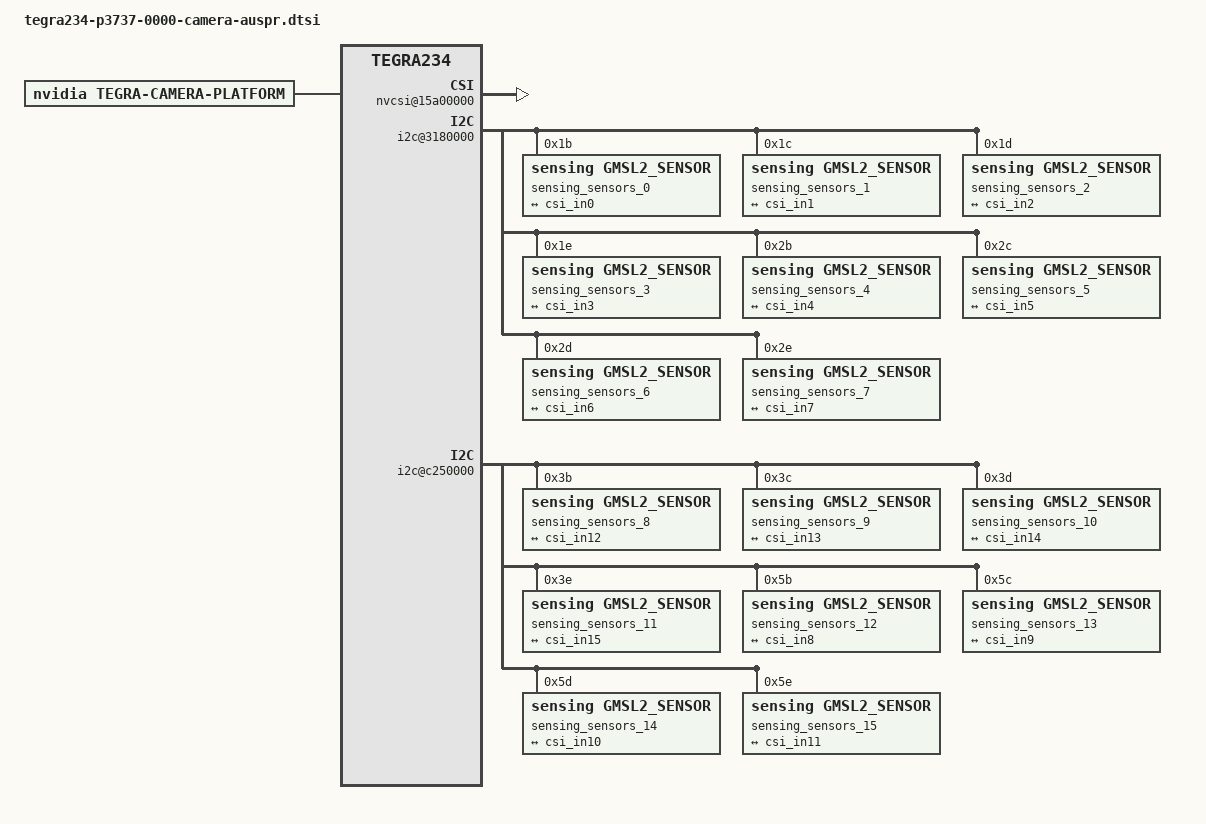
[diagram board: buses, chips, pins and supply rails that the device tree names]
/*
 * Top level DTS file for CVM:P3701-0000 and CVB:P3737-0000.
 *
 * Copyright (c) 2021-2023, NVIDIA CORPORATION.  All rights reserved.
 *
 * This program is free software; you can redistribute it and/or modify
 * it under the terms of the GNU General Public License as published by
 * the Free Software Foundation; version 2 of the License.
 *
 * This program is distributed in the hope that it will be useful, but WITHOUT
 * ANY WARRANTY; without even the implied warranty of MERCHANTABILITY or
 * FITNESS FOR A PARTICULAR PURPOSE.  See the GNU General Public License for
 * more details.
 */



/ {

	tegra-capture-vi {
		status = "okay";
        num-channels = <16>;
        ports {
          #address-cells = <1>;
          #size-cells = <0>;
          port@0 {
            reg = <0>;
            vi_in0: endpoint {
              port-index = <0>;
              bus-width = <4>;
              vc-id = <0>;
              remote-endpoint = <&csi_out0>;
            };
          };
          port@1 {
            reg = <1>;
            vi_in1: endpoint {
              port-index = <0>;
              bus-width = <4>;
              vc-id = <1>;
              remote-endpoint = <&csi_out1>;
            };
          };
          port@2 {
            reg = <2>;
            vi_in2: endpoint {
              port-index = <0>;
              bus-width = <4>;
              vc-id = <2>;
              remote-endpoint = <&csi_out2>;
            };
          };
          port@3 {
            reg = <3>;
            vi_in3: endpoint {
              port-index = <0>;
              bus-width = <4>;
              vc-id = <3>;
              remote-endpoint = <&csi_out3>;
            };
          };
          port@4 {
            reg = <4>;
            vi_in4: endpoint {
              port-index = <2>;
              bus-width = <4>;
              vc-id = <0>;
              remote-endpoint = <&csi_out4>;
            };
          };
          port@5 {
            reg = <5>;
            vi_in5: endpoint {
              port-index = <2>;
              bus-width = <4>;
              vc-id = <1>;
              remote-endpoint = <&csi_out5>;
            };
          };
          port@6 {
            reg = <6>;
            vi_in6: endpoint {
              port-index = <2>;
              bus-width = <4>;
              vc-id = <2>;
              remote-endpoint = <&csi_out6>;
            };
          };
          port@7 {
            reg = <7>;
            vi_in7: endpoint {
              port-index = <2>;
              bus-width = <4>;
              vc-id = <3>;
              remote-endpoint = <&csi_out7>;
            };
          };
          port@8 {
            reg = <8>;
            vi_in8: endpoint {
              port-index = <4>;
              bus-width = <4>;
              vc-id = <0>;
              remote-endpoint = <&csi_out8>;
            };
          };
          port@9 {
            reg = <9>;
            vi_in9: endpoint {
              port-index = <4>;
              bus-width = <4>;
              vc-id = <1>;
              remote-endpoint = <&csi_out9>;
            };
          };
          port@10 {
            reg = <10>;
            vi_in10: endpoint {
              port-index = <4>;
              bus-width = <4>;
              vc-id = <2>;
              remote-endpoint = <&csi_out10>;
            };
          };
          port@11 {
            reg = <11>;
            vi_in11: endpoint {
              port-index = <4>;
              bus-width = <4>;
              vc-id = <3>;
              remote-endpoint = <&csi_out11>;
            };
          };
          port@12 {
            reg = <12>;
            vi_in12: endpoint {
              port-index = <5>;
              bus-width = <4>;
              vc-id = <0>;
              remote-endpoint = <&csi_out12>;
            };
          };
		  port@13 {
            reg = <13>;
            vi_in13: endpoint {
              port-index = <5>;
              bus-width = <4>;
              vc-id = <1>;
              remote-endpoint = <&csi_out13>;
            };
          };
		  port@14 {
            reg = <14>;
            vi_in14: endpoint {
              port-index = <5>;
              bus-width = <4>;
              vc-id = <2>;
              remote-endpoint = <&csi_out14>;
            };
          };
		  port@15 {
            reg = <15>;
            vi_in15: endpoint {
              port-index = <5>;
              bus-width = <4>;
              vc-id = <3>;
              remote-endpoint = <&csi_out15>;
            };
          };
        };
	};


	//-------------------------------

	host1x@13e00000 {
		nvcsi@15a00000 {
			status = "okay";
        #address-cells = <1>;
        #size-cells = <0>;
        num-channels = <16>;
        channel@0 {
          reg = <0>;
          ports {
            #address-cells = <1>;
            #size-cells = <0>;
            port@0 {
              reg = <0>;
              csi_in0: endpoint@0 {
                port-index = <0>;
                bus-width = <4>;
                remote-endpoint = <&camera_out0>;
              };
            };
            port@1 {
              reg = <1>;
              csi_out0: endpoint@1 {
                remote-endpoint = <&vi_in0>;
              };
            };
          };
        };
        channel@1 {
          reg = <1>;
          ports {
            #address-cells = <1>;
            #size-cells = <0>;
            port@0 {
              reg = <0>;
              csi_in1: endpoint@0 {
                port-index = <0>;
                bus-width = <4>;
                remote-endpoint = <&camera_out1>;
              };
            };
            port@1 {
              reg = <1>;
              csi_out1: endpoint@1 {
                remote-endpoint = <&vi_in1>;
              };
            };
          };
        };
        channel@2 {
          reg = <2>;
          ports {
            #address-cells = <1>;
            #size-cells = <0>;
            port@0 {
              reg = <0>;
              csi_in2: endpoint@0 {
                port-index = <0>;
                bus-width = <4>;
                remote-endpoint = <&camera_out2>;
              };
            };
            port@1 {
              reg = <1>;
              csi_out2: endpoint@1 {
                remote-endpoint = <&vi_in2>;
              };
            };
          };
        };
        channel@3 {
          reg = <3>;
          ports {
            #address-cells = <1>;
            #size-cells = <0>;
            port@0 {
              reg = <0>;
              csi_in3: endpoint@0 {
                port-index = <0>;
                bus-width = <4>;
                remote-endpoint = <&camera_out3>;
              };
            };
            port@1 {
              reg = <1>;
              csi_out3: endpoint@1 {
                remote-endpoint = <&vi_in3>;
              };
            };
          };
        };      
        channel@4 {
          reg = <4>;
          ports {
            #address-cells = <1>;
            #size-cells = <0>;
            port@0 {
              reg = <0>;
              csi_in4: endpoint@0 {
                port-index = <2>;
                bus-width = <4>;
                remote-endpoint = <&camera_out4>;
              };
            };
            port@1 {
              reg = <1>;
              csi_out4: endpoint@1 {
                remote-endpoint = <&vi_in4>;
              };
            };
          };
        };
        channel@5 {
          reg = <5>;
          ports {
            #address-cells = <1>;
            #size-cells = <0>;
            port@0 {
              reg = <0>;              
              csi_in5: endpoint@0 {
                port-index = <2>;
                bus-width = <4>;
                remote-endpoint = <&camera_out5>;
              };
            };
            port@1 {
              reg = <1>;
              csi_out5: endpoint@1 {
                remote-endpoint = <&vi_in5>;
              };
            };
          };
        };
        channel@6 {
          reg = <6>;
          ports {
            #address-cells = <1>;
            #size-cells = <0>;
            port@0 {
              reg = <0>;
              csi_in6: endpoint@0 {
                port-index = <2>;
                bus-width = <4>;
                remote-endpoint = <&camera_out6>;
              };
            };
            port@1 {
              reg = <1>;
              csi_out6: endpoint@1 {
                remote-endpoint = <&vi_in6>;
              };
            };
          };
        };
        channel@7 {
          reg = <7>;
          ports {
            #address-cells = <1>;
            #size-cells = <0>;
            port@0 {
              reg = <0>;
              csi_in7: endpoint@0 {
                port-index = <2>;
                bus-width = <4>;
                remote-endpoint = <&camera_out7>;
              };
            };
            port@1 {
              reg = <1>;
              csi_out7: endpoint@1 {
                remote-endpoint = <&vi_in7>;
              };
            };
          };
        }; 
        channel@8 {
          reg = <8>;
          ports {
            #address-cells = <1>;
            #size-cells = <0>;
            port@0 {
              reg = <0>;
              csi_in8: endpoint@0 {
                port-index = <4>;
                vc-id = <0>;
                bus-width = <4>;
                remote-endpoint = <&camera_out12>; // workaround for SerDes 2&3 MIPI layout reversed
              };
            };
            port@1 {
              reg = <1>;
              csi_out8: endpoint@1 {
                remote-endpoint = <&vi_in8>;
              };
            };
          };
        };
        channel@9 {
          reg = <9>;
          ports {
            #address-cells = <1>;
            #size-cells = <0>;
            port@0 {
              reg = <0>;
              csi_in9: endpoint@0 {
                port-index = <4>;
                vc-id = <1>;
                bus-width = <4>;
                remote-endpoint = <&camera_out13>; // workaround for SerDes 2&3 MIPI layout reversed
              };
            };
            port@1 {
              reg = <1>;
              csi_out9: endpoint@1 {
                remote-endpoint = <&vi_in9>;
              };
            };
          };
        };
        channel@10 {
          reg = <10>;
          ports {
            #address-cells = <1>;
            #size-cells = <0>;
            port@0 {
              reg = <0>;
              csi_in10: endpoint@0 {
                port-index = <4>;
                vc-id = <2>;
                bus-width = <4>;
                remote-endpoint = <&camera_out14>; // workaround for SerDes 2&3 MIPI layout reversed
              };
            };
            port@1 {
              reg = <1>;
              csi_out10: endpoint@1 {
                remote-endpoint = <&vi_in10>;
              };
            };
          };
        };
        channel@11 {
          reg = <11>;
          ports {
            #address-cells = <1>;
            #size-cells = <0>;
            port@0 {
              reg = <0>;
              csi_in11: endpoint@0 {
                port-index = <4>;
                vc-id = <3>;
                bus-width = <4>;
                remote-endpoint = <&camera_out15>; // workaround for SerDes 2&3 MIPI layout reversed
              };
            };
            port@1 {
              reg = <1>;
              csi_out11: endpoint@1 {
                remote-endpoint = <&vi_in11>;
              };
            };
          };
        };
        channel@12 {
          reg = <12>;
          ports {
            #address-cells = <1>;
            #size-cells = <0>;
            port@0 {
              reg = <0>;
              csi_in12: endpoint@0 {
                port-index = <6>;
                vc-id = <0>;
                bus-width = <4>;
                remote-endpoint = <&camera_out8>; // workaround for SerDes 2&3 MIPI layout reversed
              };
            };
            port@1 {
              reg = <1>;
              csi_out12: endpoint@1 {
                remote-endpoint = <&vi_in12>;
              };
            };
          };
        };
        channel@13 {
          reg = <13>;
          ports {
            #address-cells = <1>;
            #size-cells = <0>;
            port@0 {
              reg = <0>;
              csi_in13: endpoint@0 {
                port-index = <6>;
                vc-id = <1>;
                bus-width = <4>;
                remote-endpoint = <&camera_out9>; // workaround for SerDes 2&3 MIPI layout reversed
              };
            };
            port@1 {
              reg = <1>;
              csi_out13: endpoint@1 {
                remote-endpoint = <&vi_in13>;
              };
            };
          };
        };
        channel@14 {
          reg = <14>;
          ports {
            #address-cells = <1>;
            #size-cells = <0>;
            port@0 {
              reg = <0>;
              csi_in14: endpoint@0 {
                port-index = <6>;
                vc-id = <2>;
                bus-width = <4>;
                remote-endpoint = <&camera_out10>; // workaround for SerDes 2&3 MIPI layout reversed
              };
            };
            port@1 {
              reg = <1>;
              csi_out14: endpoint@1 {
                remote-endpoint = <&vi_in14>;
              };
            };
          };
        };
        channel@15 {
          reg = <15>;
          ports {
            #address-cells = <1>;
            #size-cells = <0>;
            port@0 {
              reg = <0>;
              csi_in15: endpoint@0 {
                port-index = <6>;
                vc-id = <3>;
                bus-width = <4>;
                remote-endpoint = <&camera_out11>; // workaround for SerDes 2&3 MIPI layout reversed
              };
            };
            port@1 {
              reg = <1>;
              csi_out15: endpoint@1 {
                remote-endpoint = <&vi_in15>;
              };
            };
          };
        };
		};
	};

	//--------------------
	i2c@3180000 {
		sensing_sensors_0 {
					status = "okay";
  					compatible = "sensing,gmsl2_sensor";
					clocks = <&bpmp_clks TEGRA234_CLK_EXTPERIPH1>,
							 <&bpmp_clks TEGRA234_CLK_EXTPERIPH1>;
					clock-names = "extperiph1", "pllp_grtba";
					mclk = "extperiph1";
					
  					reg = <0x1b>;
					
  					devnode = "video0";
  
  					/* Physical dimensions of sensor */
  					physical_w = "15.0";
  					physical_h = "12.5";
  					sensor_model = "gmsl2_sensor";
  
  					/* Defines number of frames to be dropped by driver internally after applying */
  					/* sensor crop settings. Some sensors send corrupt frames after applying */
  					/* crop co-ordinates */
  					post_crop_frame_drop = "0";
  
  					/* Convert Gain to unit of dB (decibel) befor passing to kernel driver */
  					use_decibel_gain = "true";
  
  					/* enable CID_SENSOR_MODE_ID for sensor modes selection */
  					use_sensor_mode_id = "false";
  
  					mode0 {
  						mclk_khz = "24000";
  						num_lanes = "4";
  						tegra_sinterface = "serial_a";
  						vc_id = "0";
  						discontinuous_clk = "no";
  						dpcm_enable = "false";
  						cil_settletime = "0";
  						dynamic_pixel_bit_depth = "16";
  						csi_pixel_bit_depth = "16";
  						mode_type = "yuv";
  						pixel_phase = "uyvy";
  
  						active_w = "2880";
  						active_h = "1860";
  						readout_orientation = "0";
  						line_length = "2880";
  						inherent_gain = "1";
  						mclk_multiplier = "6.696";
  						pix_clk_hz = "160704000";
  						serdes_pix_clk_hz = "375000000";
  
  						gain_factor = "10";
  						min_gain_val = "0"; /* dB */
  						max_gain_val = "300"; /* dB */
  						step_gain_val = "3"; /* 0.3 */
  						default_gain = "0";
  						min_hdr_ratio = "1";
  						max_hdr_ratio = "1";
  						framerate_factor = "1000000";
  						min_framerate = "30000000";
  						max_framerate = "30000000";
  						step_framerate = "1";
  						default_framerate = "30000000";
  						exposure_factor = "1000000";
  						min_exp_time = "59"; /*us, 2 lines*/
  						max_exp_time = "33333";
  						step_exp_time = "1";
  						default_exp_time = "33333";/* us */
  						embedded_metadata_height = "0";
  					};
  
  					mode1 {
  						mclk_khz = "24000";
  						num_lanes = "4";
  						tegra_sinterface = "serial_a";
  						vc_id = "0";
  						discontinuous_clk = "yes";
  						dpcm_enable = "false";
  						cil_settletime = "0";
  						dynamic_pixel_bit_depth = "16";
  						csi_pixel_bit_depth = "16";
  						mode_type = "yuv";
  						pixel_phase = "uyvy";
  
  						active_w = "3840";
  						active_h = "2160";
  						readout_orientation = "0";
  						line_length = "3840";
  						inherent_gain = "1";
  						mclk_multiplier = "10.368";
  						pix_clk_hz = "248832000";
  						serdes_pix_clk_hz = "600000000";
  
  						gain_factor = "10";
  						min_gain_val = "0"; /* dB */
  						max_gain_val = "300"; /* dB */
  						step_gain_val = "3"; /* 0.3 */
  						default_gain = "0";
  						min_hdr_ratio = "1";
  						max_hdr_ratio = "1";
  						framerate_factor = "1000000";
  						min_framerate = "30000000";
  						max_framerate = "30000000";
  						step_framerate = "1";
  						default_framerate = "30000000";
  						exposure_factor = "1000000";
  						min_exp_time = "59"; /*us, 2 lines*/
  						max_exp_time = "33333";
  						step_exp_time = "1";
  						default_exp_time = "33333";/* us */
  						embedded_metadata_height = "0";
  					};
  
  					mode2 {
  						mclk_khz = "24000";
  						num_lanes = "4";
  						tegra_sinterface = "serial_a";
  						vc_id = "0";
  						discontinuous_clk = "no";
  						dpcm_enable = "false";
  						cil_settletime = "0";
  						dynamic_pixel_bit_depth = "16";
  						csi_pixel_bit_depth = "16";
  						mode_type = "yuv";
  						pixel_phase = "uyvy";
  
  						active_w = "1920";
  						active_h = "1536";
  						readout_orientation = "0";
  						line_length = "1920";
  						inherent_gain = "1";
  						mclk_multiplier = "3.6864";
  						pix_clk_hz = "88473600";
  						serdes_pix_clk_hz = "375000000";
  
  						gain_factor = "10";
  						min_gain_val = "0"; /* dB */
  						max_gain_val = "300"; /* dB */
  						step_gain_val = "3"; /* 0.3 */
  						default_gain = "0";
  						min_hdr_ratio = "1";
  						max_hdr_ratio = "1";
  						framerate_factor = "1000000";
  						min_framerate = "30000000";
  						max_framerate = "30000000";
  						step_framerate = "1";
  						default_framerate = "30000000";
  						exposure_factor = "1000000";
  						min_exp_time = "59"; /*us, 2 lines*/
  						max_exp_time = "33333";
  						step_exp_time = "1";
  						default_exp_time = "33333";/* us */
  						embedded_metadata_height = "0";
  					};
  
  					mode3 {
  						mclk_khz = "24000";
  						num_lanes = "4";
  						tegra_sinterface = "serial_a";
  						vc_id = "0";
  						discontinuous_clk = "no";
  						dpcm_enable = "false";
  						cil_settletime = "0";
  						dynamic_pixel_bit_depth = "16";
  						csi_pixel_bit_depth = "16";
  						mode_type = "yuv";
  						pixel_phase = "uyvy";
  
  						active_w = "1600";
  						active_h = "1300";
  						readout_orientation = "0";
  						line_length = "1600";
  						inherent_gain = "1";
  						mclk_multiplier = "2.6";
  						pix_clk_hz = "62400000";
  						serdes_pix_clk_hz = "375000000";
  
  						gain_factor = "10";
  						min_gain_val = "0"; /* dB */
  						max_gain_val = "300"; /* dB */
  						step_gain_val = "3"; /* 0.3 */
  						default_gain = "0";
  						min_hdr_ratio = "1";
  						max_hdr_ratio = "1";
  						framerate_factor = "1000000";
  						min_framerate = "30000000";
  						max_framerate = "30000000";
  						step_framerate = "1";
  						default_framerate = "30000000";
  						exposure_factor = "1000000";
  						min_exp_time = "59"; /*us, 2 lines*/
  						max_exp_time = "33333";
  						step_exp_time = "1";
  						default_exp_time = "33333";/* us */
  						embedded_metadata_height = "0";
  					};
  
  					ports {
  						#address-cells = <1>;
  						#size-cells = <0>;
  						port@0 {
  							reg = <0>;
  							camera_out0: endpoint {
  								vc-id = <0>;
  								port-index = <0>;
  								bus-width = <4>;
  								remote-endpoint = <&csi_in0>;
  							};
  						};
  					};
				  };
				  
  				sensing_sensors_1 {
					status = "okay";
  					compatible = "sensing,gmsl2_sensor";
					clocks = <&bpmp_clks TEGRA234_CLK_EXTPERIPH1>,
							 <&bpmp_clks TEGRA234_CLK_EXTPERIPH1>;
					clock-names = "extperiph1", "pllp_grtba";
					mclk = "extperiph1";
  					reg = <0x1c>;
  
  					devnode = "video1";
  
  					/* Physical dimensions of sensor */
  					physical_w = "15.0";
  					physical_h = "12.5";
  					sensor_model = "gmsl2_sensor";
  
  					/* Defines number of frames to be dropped by driver internally after applying */
  					/* sensor crop settings. Some sensors send corrupt frames after applying */
  					/* crop co-ordinates */
  					post_crop_frame_drop = "0";
  
  					/* Convert Gain to unit of dB (decibel) befor passing to kernel driver */
  					use_decibel_gain = "true";
  
  					/* enable CID_SENSOR_MODE_ID for sensor modes selection */
  					use_sensor_mode_id = "false";
  
  					mode0 {
  						mclk_khz = "24000";
  						num_lanes = "4";
  						tegra_sinterface = "serial_a";
  						vc_id = "1";
  						discontinuous_clk = "no";
  						dpcm_enable = "false";
  						cil_settletime = "0";
  						dynamic_pixel_bit_depth = "16";
  						csi_pixel_bit_depth = "16";
  						mode_type = "yuv";
  						pixel_phase = "uyvy";
  
  						active_w = "2880";
  						active_h = "1860";
  						readout_orientation = "0";
  						line_length = "2880";
  						inherent_gain = "1";
  						mclk_multiplier = "6.696";
  						pix_clk_hz = "160704000";
  						serdes_pix_clk_hz = "375000000";
  
  						gain_factor = "10";
  						min_gain_val = "0"; /* dB */
  						max_gain_val = "300"; /* dB */
  						step_gain_val = "3"; /* 0.3 */
  						default_gain = "0";
  						min_hdr_ratio = "1";
  						max_hdr_ratio = "1";
  						framerate_factor = "1000000";
  						min_framerate = "30000000";
  						max_framerate = "30000000";
  						step_framerate = "1";
  						default_framerate = "30000000";
  						exposure_factor = "1000000";
  						min_exp_time = "59"; /*us, 2 lines*/
  						max_exp_time = "33333";
  						step_exp_time = "1";
  						default_exp_time = "33333";/* us */
  						embedded_metadata_height = "0";
  					};
  
  					mode1 {
  						mclk_khz = "24000";
  						num_lanes = "4";
  						tegra_sinterface = "serial_a";
  						vc_id = "1";
  						discontinuous_clk = "yes";
  						dpcm_enable = "false";
  						cil_settletime = "0";
  						dynamic_pixel_bit_depth = "16";
  						csi_pixel_bit_depth = "16";
  						mode_type = "yuv";
  						pixel_phase = "uyvy";
  
  						active_w = "3840";
  						active_h = "2160";
  						readout_orientation = "0";
  						line_length = "3840";
  						inherent_gain = "1";
  						mclk_multiplier = "10.368";
  						pix_clk_hz = "248832000";
  						serdes_pix_clk_hz = "600000000";
  
  						gain_factor = "10";
  						min_gain_val = "0"; /* dB */
  						max_gain_val = "300"; /* dB */
  						step_gain_val = "3"; /* 0.3 */
  						default_gain = "0";
  						min_hdr_ratio = "1";
  						max_hdr_ratio = "1";
  						framerate_factor = "1000000";
  						min_framerate = "30000000";
  						max_framerate = "30000000";
  						step_framerate = "1";
  						default_framerate = "30000000";
  						exposure_factor = "1000000";
  						min_exp_time = "59"; /*us, 2 lines*/
  						max_exp_time = "33333";
  						step_exp_time = "1";
  						default_exp_time = "33333";/* us */
  						embedded_metadata_height = "0";
  					};
  
  					mode2 {
  						mclk_khz = "24000";
  						num_lanes = "4";
  						tegra_sinterface = "serial_a";
  						vc_id = "1";
  						discontinuous_clk = "no";
  						dpcm_enable = "false";
  						cil_settletime = "0";
  						dynamic_pixel_bit_depth = "16";
  						csi_pixel_bit_depth = "16";
  						mode_type = "yuv";
  						pixel_phase = "uyvy";
  
  						active_w = "1920";
  						active_h = "1536";
  						readout_orientation = "0";
  						line_length = "1920";
  						inherent_gain = "1";
  						mclk_multiplier = "3.6864";
  						pix_clk_hz = "88473600";
  						serdes_pix_clk_hz = "375000000";
  
  						gain_factor = "10";
  						min_gain_val = "0"; /* dB */
  						max_gain_val = "300"; /* dB */
  						step_gain_val = "3"; /* 0.3 */
  						default_gain = "0";
  						min_hdr_ratio = "1";
  						max_hdr_ratio = "1";
  						framerate_factor = "1000000";
  						min_framerate = "30000000";
  						max_framerate = "30000000";
  						step_framerate = "1";
  						default_framerate = "30000000";
  						exposure_factor = "1000000";
  						min_exp_time = "59"; /*us, 2 lines*/
  						max_exp_time = "33333";
  						step_exp_time = "1";
  						default_exp_time = "33333";/* us */
  						embedded_metadata_height = "0";
  					};
  
  					mode3 {
  						mclk_khz = "24000";
  						num_lanes = "4";
  						tegra_sinterface = "serial_a";
  						vc_id = "1";
  						discontinuous_clk = "no";
  						dpcm_enable = "false";
  						cil_settletime = "0";
  						dynamic_pixel_bit_depth = "16";
  						csi_pixel_bit_depth = "16";
  						mode_type = "yuv";
  						pixel_phase = "uyvy";
  
  						active_w = "1600";
  						active_h = "1300";
  						readout_orientation = "0";
  						line_length = "1600";
  						inherent_gain = "1";
  						mclk_multiplier = "2.6";
  						pix_clk_hz = "62400000";
  						serdes_pix_clk_hz = "375000000";
  
  						gain_factor = "10";
  						min_gain_val = "0"; /* dB */
  						max_gain_val = "300"; /* dB */
  						step_gain_val = "3"; /* 0.3 */
  						default_gain = "0";
  						min_hdr_ratio = "1";
  						max_hdr_ratio = "1";
  						framerate_factor = "1000000";
  						min_framerate = "30000000";
  						max_framerate = "30000000";
  						step_framerate = "1";
  						default_framerate = "30000000";
  						exposure_factor = "1000000";
  						min_exp_time = "59"; /*us, 2 lines*/
  						max_exp_time = "33333";
  						step_exp_time = "1";
  						default_exp_time = "33333";/* us */
  						embedded_metadata_height = "0";
  					};
  
  					ports {
  						#address-cells = <1>;
  						#size-cells = <0>;
  						port@0 {
  							reg = <0>;
  							camera_out1: endpoint {
  								vc-id = <1>;
  								port-index = <0>;
  								bus-width = <4>;
  								remote-endpoint = <&csi_in1>;
  							};
  						};
  					};
  				};
  
  				sensing_sensors_2 {
					status = "okay";
  					compatible = "sensing,gmsl2_sensor";
					clocks = <&bpmp_clks TEGRA234_CLK_EXTPERIPH1>,
							 <&bpmp_clks TEGRA234_CLK_EXTPERIPH1>;
					clock-names = "extperiph1", "pllp_grtba";
					mclk = "extperiph1";
  					reg = <0x1d>;
  
  					devnode = "video2";
  
  					/* Physical dimensions of sensor */
  					physical_w = "15.0";
  					physical_h = "12.5";
  					sensor_model = "gmsl2_sensor";
  
  					/* Defines number of frames to be dropped by driver internally after applying */
  					/* sensor crop settings. Some sensors send corrupt frames after applying */
  					/* crop co-ordinates */
  					post_crop_frame_drop = "0";
  
  					/* Convert Gain to unit of dB (decibel) befor passing to kernel driver */
  					use_decibel_gain = "true";
  
  					/* enable CID_SENSOR_MODE_ID for sensor modes selection */
  					use_sensor_mode_id = "false";
  
  					mode0 {
  						mclk_khz = "24000";
  						num_lanes = "4";
  						tegra_sinterface = "serial_a";
  						vc_id = "2";
  						discontinuous_clk = "no";
  						dpcm_enable = "false";
  						cil_settletime = "0";
  						dynamic_pixel_bit_depth = "16";
  						csi_pixel_bit_depth = "16";
  						mode_type = "yuv";
  						pixel_phase = "uyvy";
  
  						active_w = "2880";
  						active_h = "1860";
  						readout_orientation = "0";
  						line_length = "2880";
  						inherent_gain = "1";
  						mclk_multiplier = "6.696";
  						pix_clk_hz = "160704000";
  						serdes_pix_clk_hz = "375000000";
  
  						gain_factor = "10";
  						min_gain_val = "0"; /* dB */
  						max_gain_val = "300"; /* dB */
  						step_gain_val = "3"; /* 0.3 */
  						default_gain = "0";
  						min_hdr_ratio = "1";
  						max_hdr_ratio = "1";
  						framerate_factor = "1000000";
  						min_framerate = "30000000";
  						max_framerate = "30000000";
  						step_framerate = "1";
  						default_framerate = "30000000";
  						exposure_factor = "1000000";
  						min_exp_time = "59"; /*us, 2 lines*/
  						max_exp_time = "33333";
  						step_exp_time = "1";
  						default_exp_time = "33333";/* us */
  						embedded_metadata_height = "0";
  					};
  
  					mode1 {
  						mclk_khz = "24000";
  						num_lanes = "4";
  						tegra_sinterface = "serial_a";
  						vc_id = "2";
  						discontinuous_clk = "yes";
  						dpcm_enable = "false";
  						cil_settletime = "0";
  						dynamic_pixel_bit_depth = "16";
  						csi_pixel_bit_depth = "16";
  						mode_type = "yuv";
  						pixel_phase = "uyvy";
  
  						active_w = "3840";
  						active_h = "2160";
  						readout_orientation = "0";
  						line_length = "3840";
  						inherent_gain = "1";
  						mclk_multiplier = "10.368";
  						pix_clk_hz = "248832000";
  						serdes_pix_clk_hz = "600000000";
  
  						gain_factor = "10";
  						min_gain_val = "0"; /* dB */
  						max_gain_val = "300"; /* dB */
  						step_gain_val = "3"; /* 0.3 */
  						default_gain = "0";
  						min_hdr_ratio = "1";
  						max_hdr_ratio = "1";
  						framerate_factor = "1000000";
  						min_framerate = "30000000";
  						max_framerate = "30000000";
  						step_framerate = "1";
  						default_framerate = "30000000";
  						exposure_factor = "1000000";
  						min_exp_time = "59"; /*us, 2 lines*/
  						max_exp_time = "33333";
  						step_exp_time = "1";
  						default_exp_time = "33333";/* us */
  						embedded_metadata_height = "0";
  					};
  
  					mode2 {
  						mclk_khz = "24000";
  						num_lanes = "4";
  						tegra_sinterface = "serial_a";
  						vc_id = "2";
  						discontinuous_clk = "no";
  						dpcm_enable = "false";
  						cil_settletime = "0";
  						dynamic_pixel_bit_depth = "16";
  						csi_pixel_bit_depth = "16";
  						mode_type = "yuv";
  						pixel_phase = "uyvy";
  
  						active_w = "1920";
  						active_h = "1536";
  						readout_orientation = "0";
  						line_length = "1920";
  						inherent_gain = "1";
  						mclk_multiplier = "3.6864";
  						pix_clk_hz = "88473600";
  						serdes_pix_clk_hz = "375000000";
  
  						gain_factor = "10";
  						min_gain_val = "0"; /* dB */
  						max_gain_val = "300"; /* dB */
  						step_gain_val = "3"; /* 0.3 */
  						default_gain = "0";
  						min_hdr_ratio = "1";
  						max_hdr_ratio = "1";
  						framerate_factor = "1000000";
  						min_framerate = "30000000";
  						max_framerate = "30000000";
  						step_framerate = "1";
  						default_framerate = "30000000";
  						exposure_factor = "1000000";
  						min_exp_time = "59"; /*us, 2 lines*/
  						max_exp_time = "33333";
  						step_exp_time = "1";
  						default_exp_time = "33333";/* us */
  						embedded_metadata_height = "0";
  					};
  
  					mode3 {
  						mclk_khz = "24000";
  						num_lanes = "4";
  						tegra_sinterface = "serial_a";
  						vc_id = "2";
  						discontinuous_clk = "no";
  						dpcm_enable = "false";
  						cil_settletime = "0";
  						dynamic_pixel_bit_depth = "16";
  						csi_pixel_bit_depth = "16";
  						mode_type = "yuv";
  						pixel_phase = "uyvy";
  
  						active_w = "1600";
  						active_h = "1300";
  						readout_orientation = "0";
  						line_length = "1600";
  						inherent_gain = "1";
  						mclk_multiplier = "2.6";
  						pix_clk_hz = "62400000";
  						serdes_pix_clk_hz = "375000000";
  
  						gain_factor = "10";
  						min_gain_val = "0"; /* dB */
  						max_gain_val = "300"; /* dB */
  						step_gain_val = "3"; /* 0.3 */
  						default_gain = "0";
  						min_hdr_ratio = "1";
  						max_hdr_ratio = "1";
  						framerate_factor = "1000000";
  						min_framerate = "30000000";
  						max_framerate = "30000000";
  						step_framerate = "1";
  						default_framerate = "30000000";
  						exposure_factor = "1000000";
  						min_exp_time = "59"; /*us, 2 lines*/
  						max_exp_time = "33333";
  						step_exp_time = "1";
  						default_exp_time = "33333";/* us */
  						embedded_metadata_height = "0";
  					};
  
  					ports {
  						#address-cells = <1>;
  						#size-cells = <0>;
  						port@0 {
  							reg = <0>;
  							camera_out2: endpoint {
  								vc-id = <2>;
  								port-index = <0>;
  								bus-width = <4>;
  								remote-endpoint = <&csi_in2>;
  							};
  						};
  					};
  				};
  
  				sensing_sensors_3 {
					status = "okay";
  					compatible = "sensing,gmsl2_sensor";
					clocks = <&bpmp_clks TEGRA234_CLK_EXTPERIPH1>,
							 <&bpmp_clks TEGRA234_CLK_EXTPERIPH1>;
					clock-names = "extperiph1", "pllp_grtba";
					mclk = "extperiph1";
  					reg = <0x1e>;
  
  					devnode = "video3";
  
  					/* Physical dimensions of sensor */
  					physical_w = "15.0";
  					physical_h = "12.5";
  					sensor_model = "gmsl2_sensor";
  
  					/* Defines number of frames to be dropped by driver internally after applying */
  					/* sensor crop settings. Some sensors send corrupt frames after applying */
  					/* crop co-ordinates */
  					post_crop_frame_drop = "0";
  
  					/* Convert Gain to unit of dB (decibel) befor passing to kernel driver */
  					use_decibel_gain = "true";
  
  					/* enable CID_SENSOR_MODE_ID for sensor modes selection */
  					use_sensor_mode_id = "false";
  
  					mode0 {
  						mclk_khz = "24000";
  						num_lanes = "4";
  						tegra_sinterface = "serial_a";
  						vc_id = "3";
  						discontinuous_clk = "no";
  						dpcm_enable = "false";
  						cil_settletime = "0";
  						dynamic_pixel_bit_depth = "16";
  						csi_pixel_bit_depth = "16";
  						mode_type = "yuv";
  						pixel_phase = "uyvy";
  
  						active_w = "2880";
  						active_h = "1860";
  						readout_orientation = "0";
  						line_length = "2880";
  						inherent_gain = "1";
  						mclk_multiplier = "6.696";
  						pix_clk_hz = "160704000";
  						serdes_pix_clk_hz = "375000000";
  
  						gain_factor = "10";
  						min_gain_val = "0"; /* dB */
  						max_gain_val = "300"; /* dB */
  						step_gain_val = "3"; /* 0.3 */
  						default_gain = "0";
  						min_hdr_ratio = "1";
  						max_hdr_ratio = "1";
  						framerate_factor = "1000000";
  						min_framerate = "30000000";
  						max_framerate = "30000000";
  						step_framerate = "1";
  						default_framerate = "30000000";
  						exposure_factor = "1000000";
  						min_exp_time = "59"; /*us, 2 lines*/
  						max_exp_time = "33333";
  						step_exp_time = "1";
  						default_exp_time = "33333";/* us */
  						embedded_metadata_height = "0";
  					};
  
  					mode1 {
  						mclk_khz = "24000";
  						num_lanes = "4";
  						tegra_sinterface = "serial_a";
  						vc_id = "3";
  						discontinuous_clk = "yes";
  						dpcm_enable = "false";
  						cil_settletime = "0";
  						dynamic_pixel_bit_depth = "16";
  						csi_pixel_bit_depth = "16";
  						mode_type = "yuv";
  						pixel_phase = "uyvy";
  
  						active_w = "3840";
  						active_h = "2160";
  						readout_orientation = "0";
  						line_length = "3840";
  						inherent_gain = "1";
  						mclk_multiplier = "10.368";
  						pix_clk_hz = "248832000";
  						serdes_pix_clk_hz = "600000000";
  
  						gain_factor = "10";
  						min_gain_val = "0"; /* dB */
  						max_gain_val = "300"; /* dB */
  						step_gain_val = "3"; /* 0.3 */
  						default_gain = "0";
  						min_hdr_ratio = "1";
  						max_hdr_ratio = "1";
  						framerate_factor = "1000000";
  						min_framerate = "30000000";
  						max_framerate = "30000000";
  						step_framerate = "1";
  						default_framerate = "30000000";
  						exposure_factor = "1000000";
  						min_exp_time = "59"; /*us, 2 lines*/
  						max_exp_time = "33333";
  						step_exp_time = "1";
  						default_exp_time = "33333";/* us */
  						embedded_metadata_height = "0";
  					};
  
  					mode2 {
  						mclk_khz = "24000";
  						num_lanes = "4";
  						tegra_sinterface = "serial_a";
  						vc_id = "3";
  						discontinuous_clk = "no";
  						dpcm_enable = "false";
  						cil_settletime = "0";
  						dynamic_pixel_bit_depth = "16";
  						csi_pixel_bit_depth = "16";
  						mode_type = "yuv";
  						pixel_phase = "uyvy";
  
  						active_w = "1920";
  						active_h = "1536";
  						readout_orientation = "0";
  						line_length = "1920";
  						inherent_gain = "1";
  						mclk_multiplier = "3.6864";
  						pix_clk_hz = "88473600";
  						serdes_pix_clk_hz = "375000000";
  
  						gain_factor = "10";
  						min_gain_val = "0"; /* dB */
  						max_gain_val = "300"; /* dB */
  						step_gain_val = "3"; /* 0.3 */
  						default_gain = "0";
  						min_hdr_ratio = "1";
  						max_hdr_ratio = "1";
  						framerate_factor = "1000000";
  						min_framerate = "30000000";
  						max_framerate = "30000000";
  						step_framerate = "1";
  						default_framerate = "30000000";
  						exposure_factor = "1000000";
  						min_exp_time = "59"; /*us, 2 lines*/
  						max_exp_time = "33333";
  						step_exp_time = "1";
  						default_exp_time = "33333";/* us */
  						embedded_metadata_height = "0";
  					};
  
  					mode3 {
  						mclk_khz = "24000";
  						num_lanes = "4";
  						tegra_sinterface = "serial_a";
  						vc_id = "3";
  						discontinuous_clk = "no";
  						dpcm_enable = "false";
  						cil_settletime = "0";
  						dynamic_pixel_bit_depth = "16";
  						csi_pixel_bit_depth = "16";
  						mode_type = "yuv";
  						pixel_phase = "uyvy";
  
  						active_w = "1600";
  						active_h = "1300";
  						readout_orientation = "0";
  						line_length = "1600";
  						inherent_gain = "1";
  						mclk_multiplier = "2.6";
  						pix_clk_hz = "62400000";
  						serdes_pix_clk_hz = "375000000";
  
  						gain_factor = "10";
  						min_gain_val = "0"; /* dB */
  						max_gain_val = "300"; /* dB */
  						step_gain_val = "3"; /* 0.3 */
  						default_gain = "0";
  						min_hdr_ratio = "1";
  						max_hdr_ratio = "1";
  						framerate_factor = "1000000";
  						min_framerate = "30000000";
  						max_framerate = "30000000";
  						step_framerate = "1";
  						default_framerate = "30000000";
  						exposure_factor = "1000000";
  						min_exp_time = "59"; /*us, 2 lines*/
  						max_exp_time = "33333";
  						step_exp_time = "1";
  						default_exp_time = "33333";/* us */
  						embedded_metadata_height = "0";
  					};
  
  					ports {
  						#address-cells = <1>;
  						#size-cells = <0>;
  						port@0 {
  							reg = <0>;
  							camera_out3: endpoint {
  								vc-id = <3>;
  								port-index = <0>;
  								bus-width = <4>;
  								remote-endpoint = <&csi_in3>;
  							};
  						};
  					};
  				};
  				
  				sensing_sensors_4 {
					status = "okay";
  					compatible = "sensing,gmsl2_sensor";
					clocks = <&bpmp_clks TEGRA234_CLK_EXTPERIPH1>,
							 <&bpmp_clks TEGRA234_CLK_EXTPERIPH1>;
					clock-names = "extperiph1", "pllp_grtba";
					mclk = "extperiph1";
  					reg = <0x2b>;
  
  					devnode = "video4";
  
  					/* Physical dimensions of sensor */
  					physical_w = "15.0";
  					physical_h = "12.5";
  					sensor_model = "gmsl2_sensor";
  
  					/* Defines number of frames to be dropped by driver internally after applying */
  					/* sensor crop settings. Some sensors send corrupt frames after applying */
  					/* crop co-ordinates */
  					post_crop_frame_drop = "0";
  
  					/* Convert Gain to unit of dB (decibel) befor passing to kernel driver */
  					use_decibel_gain = "true";
  
  					/* enable CID_SENSOR_MODE_ID for sensor modes selection */
  					use_sensor_mode_id = "false";
  
  					mode0 {
  						mclk_khz = "24000";
  						num_lanes = "4";
  						tegra_sinterface = "serial_c";
  						vc_id = "0";
  						discontinuous_clk = "no";
  						dpcm_enable = "false";
  						cil_settletime = "0";
  						dynamic_pixel_bit_depth = "16";
  						csi_pixel_bit_depth = "16";
  						mode_type = "yuv";
  						pixel_phase = "uyvy";
  
  						active_w = "2880";
  						active_h = "1860";
  						readout_orientation = "0";
  						line_length = "2880";
  						inherent_gain = "1";
  						mclk_multiplier = "6.696";
  						pix_clk_hz = "160704000";
  						serdes_pix_clk_hz = "375000000";
  
  						gain_factor = "10";
  						min_gain_val = "0"; /* dB */
  						max_gain_val = "300"; /* dB */
  						step_gain_val = "3"; /* 0.3 */
  						default_gain = "0";
  						min_hdr_ratio = "1";
  						max_hdr_ratio = "1";
  						framerate_factor = "1000000";
  						min_framerate = "30000000";
  						max_framerate = "30000000";
  						step_framerate = "1";
  						default_framerate = "30000000";
  						exposure_factor = "1000000";
  						min_exp_time = "59"; /*us, 2 lines*/
  						max_exp_time = "33333";
  						step_exp_time = "1";
  						default_exp_time = "33333";/* us */
  						embedded_metadata_height = "0";
  					};
  
  					mode1 {
  						mclk_khz = "24000";
  						num_lanes = "4";
  						tegra_sinterface = "serial_c";
  						vc_id = "0";
  						discontinuous_clk = "yes";
  						dpcm_enable = "false";
  						cil_settletime = "0";
  						dynamic_pixel_bit_depth = "16";
  						csi_pixel_bit_depth = "16";
  						mode_type = "yuv";
  						pixel_phase = "uyvy";
  
  						active_w = "3840";
  						active_h = "2160";
  						readout_orientation = "0";
  						line_length = "3840";
  						inherent_gain = "1";
  						mclk_multiplier = "10.368";
  						pix_clk_hz = "248832000";
  						serdes_pix_clk_hz = "600000000";
  
  						gain_factor = "10";
  						min_gain_val = "0"; /* dB */
  						max_gain_val = "300"; /* dB */
  						step_gain_val = "3"; /* 0.3 */
  						default_gain = "0";
  						min_hdr_ratio = "1";
  						max_hdr_ratio = "1";
  						framerate_factor = "1000000";
  						min_framerate = "30000000";
  						max_framerate = "30000000";
  						step_framerate = "1";
  						default_framerate = "30000000";
  						exposure_factor = "1000000";
  						min_exp_time = "59"; /*us, 2 lines*/
  						max_exp_time = "33333";
  						step_exp_time = "1";
  						default_exp_time = "33333";/* us */
  						embedded_metadata_height = "0";
  					};
  
  					mode2 {
  						mclk_khz = "24000";
  						num_lanes = "4";
  						tegra_sinterface = "serial_c";
  						vc_id = "0";
  						discontinuous_clk = "no";
  						dpcm_enable = "false";
  						cil_settletime = "0";
  						dynamic_pixel_bit_depth = "16";
  						csi_pixel_bit_depth = "16";
  						mode_type = "yuv";
  						pixel_phase = "uyvy";
  
  						active_w = "1920";
  						active_h = "1536";
  						readout_orientation = "0";
  						line_length = "1920";
  						inherent_gain = "1";
  						mclk_multiplier = "3.6864";
  						pix_clk_hz = "88473600";
  						serdes_pix_clk_hz = "375000000";
  
  						gain_factor = "10";
  						min_gain_val = "0"; /* dB */
  						max_gain_val = "300"; /* dB */
  						step_gain_val = "3"; /* 0.3 */
  						default_gain = "0";
  						min_hdr_ratio = "1";
  						max_hdr_ratio = "1";
  						framerate_factor = "1000000";
  						min_framerate = "30000000";
  						max_framerate = "30000000";
  						step_framerate = "1";
  						default_framerate = "30000000";
  						exposure_factor = "1000000";
  						min_exp_time = "59"; /*us, 2 lines*/
  						max_exp_time = "33333";
  						step_exp_time = "1";
  						default_exp_time = "33333";/* us */
  						embedded_metadata_height = "0";
  					};
  
  					mode3 {
  						mclk_khz = "24000";
  						num_lanes = "4";
  						tegra_sinterface = "serial_c";
  						vc_id = "0";
  						discontinuous_clk = "no";
  						dpcm_enable = "false";
  						cil_settletime = "0";
  						dynamic_pixel_bit_depth = "16";
  						csi_pixel_bit_depth = "16";
  						mode_type = "yuv";
  						pixel_phase = "uyvy";
  
  						active_w = "1600";
  						active_h = "1300";
  						readout_orientation = "0";
  						line_length = "1600";
  						inherent_gain = "1";
  						mclk_multiplier = "2.6";
  						pix_clk_hz = "62400000";
  						serdes_pix_clk_hz = "375000000";
  
  						gain_factor = "10";
  						min_gain_val = "0"; /* dB */
  						max_gain_val = "300"; /* dB */
  						step_gain_val = "3"; /* 0.3 */
  						default_gain = "0";
  						min_hdr_ratio = "1";
  						max_hdr_ratio = "1";
  						framerate_factor = "1000000";
  						min_framerate = "30000000";
  						max_framerate = "30000000";
  						step_framerate = "1";
  						default_framerate = "30000000";
  						exposure_factor = "1000000";
  						min_exp_time = "59"; /*us, 2 lines*/
  						max_exp_time = "33333";
  						step_exp_time = "1";
  						default_exp_time = "33333";/* us */
  						embedded_metadata_height = "0";
  					};
  
  					ports {
  						#address-cells = <1>;
  						#size-cells = <0>;
  						port@0 {
  							reg = <0>;
  							camera_out4: endpoint {
  								vc-id = <0>;
  								port-index = <2>;
  								bus-width = <4>;
  								remote-endpoint = <&csi_in4>;
  							};
  						};
  					};
  				};
  				
  				sensing_sensors_5 {
					status = "okay";
  					compatible = "sensing,gmsl2_sensor";
					clocks = <&bpmp_clks TEGRA234_CLK_EXTPERIPH1>,
							 <&bpmp_clks TEGRA234_CLK_EXTPERIPH1>;
					clock-names = "extperiph1", "pllp_grtba";
					mclk = "extperiph1";
  					reg = <0x2c>;
  
  					devnode = "video5";
  
  					/* Physical dimensions of sensor */
  					physical_w = "15.0";
  					physical_h = "12.5";
  					sensor_model = "gmsl2_sensor";
  
  					/* Defines number of frames to be dropped by driver internally after applying */
  					/* sensor crop settings. Some sensors send corrupt frames after applying */
  					/* crop co-ordinates */
  					post_crop_frame_drop = "0";
  
  					/* Convert Gain to unit of dB (decibel) befor passing to kernel driver */
  					use_decibel_gain = "true";
  
  					/* enable CID_SENSOR_MODE_ID for sensor modes selection */
  					use_sensor_mode_id = "false";
  
  					mode0 {
  						mclk_khz = "24000";
  						num_lanes = "4";
  						tegra_sinterface = "serial_c";
  						vc_id = "1";
  						discontinuous_clk = "no";
  						dpcm_enable = "false";
  						cil_settletime = "0";
  						dynamic_pixel_bit_depth = "16";
  						csi_pixel_bit_depth = "16";
  						mode_type = "yuv";
  						pixel_phase = "uyvy";
  
  						active_w = "2880";
  						active_h = "1860";
  						readout_orientation = "0";
  						line_length = "2880";
  						inherent_gain = "1";
  						mclk_multiplier = "6.696";
  						pix_clk_hz = "160704000";
  						serdes_pix_clk_hz = "375000000";
  
  						gain_factor = "10";
  						min_gain_val = "0"; /* dB */
  						max_gain_val = "300"; /* dB */
  						step_gain_val = "3"; /* 0.3 */
  						default_gain = "0";
  						min_hdr_ratio = "1";
  						max_hdr_ratio = "1";
  						framerate_factor = "1000000";
  						min_framerate = "30000000";
  						max_framerate = "30000000";
  						step_framerate = "1";
  						default_framerate = "30000000";
  						exposure_factor = "1000000";
  						min_exp_time = "59"; /*us, 2 lines*/
  						max_exp_time = "33333";
  						step_exp_time = "1";
  						default_exp_time = "33333";/* us */
  						embedded_metadata_height = "0";
  					};
  
  					mode1 {
  						mclk_khz = "24000";
  						num_lanes = "4";
  						tegra_sinterface = "serial_c";
  						vc_id = "1";
  						discontinuous_clk = "yes";
  						dpcm_enable = "false";
  						cil_settletime = "0";
  						dynamic_pixel_bit_depth = "16";
  						csi_pixel_bit_depth = "16";
  						mode_type = "yuv";
  						pixel_phase = "uyvy";
  
  						active_w = "3840";
  						active_h = "2160";
  						readout_orientation = "0";
  						line_length = "3840";
  						inherent_gain = "1";
  						mclk_multiplier = "10.368";
  						pix_clk_hz = "248832000";
  						serdes_pix_clk_hz = "600000000";
  
  						gain_factor = "10";
  						min_gain_val = "0"; /* dB */
  						max_gain_val = "300"; /* dB */
  						step_gain_val = "3"; /* 0.3 */
  						default_gain = "0";
  						min_hdr_ratio = "1";
  						max_hdr_ratio = "1";
  						framerate_factor = "1000000";
  						min_framerate = "30000000";
  						max_framerate = "30000000";
  						step_framerate = "1";
  						default_framerate = "30000000";
  						exposure_factor = "1000000";
  						min_exp_time = "59"; /*us, 2 lines*/
  						max_exp_time = "33333";
  						step_exp_time = "1";
  						default_exp_time = "33333";/* us */
  						embedded_metadata_height = "0";
  					};
  
  					mode2 {
  						mclk_khz = "24000";
  						num_lanes = "4";
  						tegra_sinterface = "serial_c";
  						vc_id = "1";
  						discontinuous_clk = "no";
  						dpcm_enable = "false";
  						cil_settletime = "0";
  						dynamic_pixel_bit_depth = "16";
  						csi_pixel_bit_depth = "16";
  						mode_type = "yuv";
  						pixel_phase = "uyvy";
  
  						active_w = "1920";
  						active_h = "1536";
  						readout_orientation = "0";
  						line_length = "1920";
  						inherent_gain = "1";
  						mclk_multiplier = "3.6864";
  						pix_clk_hz = "88473600";
  						serdes_pix_clk_hz = "375000000";
  
  						gain_factor = "10";
  						min_gain_val = "0"; /* dB */
  						max_gain_val = "300"; /* dB */
  						step_gain_val = "3"; /* 0.3 */
  						default_gain = "0";
  						min_hdr_ratio = "1";
  						max_hdr_ratio = "1";
  						framerate_factor = "1000000";
  						min_framerate = "30000000";
  						max_framerate = "30000000";
  						step_framerate = "1";
  						default_framerate = "30000000";
  						exposure_factor = "1000000";
  						min_exp_time = "59"; /*us, 2 lines*/
  						max_exp_time = "33333";
  						step_exp_time = "1";
  						default_exp_time = "33333";/* us */
  						embedded_metadata_height = "0";
  					};
  
  					mode3 {
  						mclk_khz = "24000";
  						num_lanes = "4";
  						tegra_sinterface = "serial_c";
  						vc_id = "1";
  						discontinuous_clk = "no";
  						dpcm_enable = "false";
  						cil_settletime = "0";
  						dynamic_pixel_bit_depth = "16";
  						csi_pixel_bit_depth = "16";
  						mode_type = "yuv";
  						pixel_phase = "uyvy";
  
  						active_w = "1600";
  						active_h = "1300";
  						readout_orientation = "0";
  						line_length = "1600";
  						inherent_gain = "1";
  						mclk_multiplier = "2.6";
  						pix_clk_hz = "62400000";
  						serdes_pix_clk_hz = "375000000";
  
  						gain_factor = "10";
  						min_gain_val = "0"; /* dB */
  						max_gain_val = "300"; /* dB */
  						step_gain_val = "3"; /* 0.3 */
  						default_gain = "0";
  						min_hdr_ratio = "1";
  						max_hdr_ratio = "1";
  						framerate_factor = "1000000";
  						min_framerate = "30000000";
  						max_framerate = "30000000";
  						step_framerate = "1";
  						default_framerate = "30000000";
  						exposure_factor = "1000000";
  						min_exp_time = "59"; /*us, 2 lines*/
  						max_exp_time = "33333";
  						step_exp_time = "1";
  						default_exp_time = "33333";/* us */
  						embedded_metadata_height = "0";
  					};
  
  					ports {
  						#address-cells = <1>;
  						#size-cells = <0>;
  						port@0 {
  							reg = <0>;
  							camera_out5: endpoint {
  								vc-id = <1>;
  								port-index = <2>;
  								bus-width = <4>;
  								remote-endpoint = <&csi_in5>;
  							};
  						};
  					};
  				};
  				
  				sensing_sensors_6 {
					status = "okay";
  					compatible = "sensing,gmsl2_sensor";
					clocks = <&bpmp_clks TEGRA234_CLK_EXTPERIPH1>,
							 <&bpmp_clks TEGRA234_CLK_EXTPERIPH1>;
					clock-names = "extperiph1", "pllp_grtba";
					mclk = "extperiph1";
  					reg = <0x2d>;
  
  					devnode = "video6";
  
  					/* Physical dimensions of sensor */
  					physical_w = "15.0";
  					physical_h = "12.5";
  					sensor_model = "gmsl2_sensor";
  
  					/* Defines number of frames to be dropped by driver internally after applying */
  					/* sensor crop settings. Some sensors send corrupt frames after applying */
  					/* crop co-ordinates */
  					post_crop_frame_drop = "0";
  
  					/* Convert Gain to unit of dB (decibel) befor passing to kernel driver */
  					use_decibel_gain = "true";
  
  					/* enable CID_SENSOR_MODE_ID for sensor modes selection */
  					use_sensor_mode_id = "false";
  
  					mode0 {
  						mclk_khz = "24000";
  						num_lanes = "4";
  						tegra_sinterface = "serial_c";
  						vc_id = "2";
  						discontinuous_clk = "no";
  						dpcm_enable = "false";
  						cil_settletime = "0";
  						dynamic_pixel_bit_depth = "16";
  						csi_pixel_bit_depth = "16";
  						mode_type = "yuv";
  						pixel_phase = "uyvy";
  
  						active_w = "2880";
  						active_h = "1860";
  						readout_orientation = "0";
  						line_length = "2880";
  						inherent_gain = "1";
  						mclk_multiplier = "6.696";
  						pix_clk_hz = "160704000";
  						serdes_pix_clk_hz = "375000000";
  
  						gain_factor = "10";
  						min_gain_val = "0"; /* dB */
  						max_gain_val = "300"; /* dB */
  						step_gain_val = "3"; /* 0.3 */
  						default_gain = "0";
  						min_hdr_ratio = "1";
  						max_hdr_ratio = "1";
  						framerate_factor = "1000000";
  						min_framerate = "30000000";
  						max_framerate = "30000000";
  						step_framerate = "1";
  						default_framerate = "30000000";
  						exposure_factor = "1000000";
  						min_exp_time = "59"; /*us, 2 lines*/
  						max_exp_time = "33333";
  						step_exp_time = "1";
  						default_exp_time = "33333";/* us */
  						embedded_metadata_height = "0";
  					};
  
  					mode1 {
  						mclk_khz = "24000";
  						num_lanes = "4";
  						tegra_sinterface = "serial_c";
  						vc_id = "2";
  						discontinuous_clk = "yes";
  						dpcm_enable = "false";
  						cil_settletime = "0";
  						dynamic_pixel_bit_depth = "16";
  						csi_pixel_bit_depth = "16";
  						mode_type = "yuv";
  						pixel_phase = "uyvy";
  
  						active_w = "3840";
  						active_h = "2160";
  						readout_orientation = "0";
  						line_length = "3840";
  						inherent_gain = "1";
  						mclk_multiplier = "10.368";
  						pix_clk_hz = "248832000";
  						serdes_pix_clk_hz = "600000000";
  
  						gain_factor = "10";
  						min_gain_val = "0"; /* dB */
  						max_gain_val = "300"; /* dB */
  						step_gain_val = "3"; /* 0.3 */
  						default_gain = "0";
  						min_hdr_ratio = "1";
  						max_hdr_ratio = "1";
  						framerate_factor = "1000000";
  						min_framerate = "30000000";
  						max_framerate = "30000000";
  						step_framerate = "1";
  						default_framerate = "30000000";
  						exposure_factor = "1000000";
  						min_exp_time = "59"; /*us, 2 lines*/
  						max_exp_time = "33333";
  						step_exp_time = "1";
  						default_exp_time = "33333";/* us */
  						embedded_metadata_height = "0";
  					};
  
  					mode2 {
  						mclk_khz = "24000";
  						num_lanes = "4";
  						tegra_sinterface = "serial_c";
  						vc_id = "2";
  						discontinuous_clk = "no";
  						dpcm_enable = "false";
  						cil_settletime = "0";
  						dynamic_pixel_bit_depth = "16";
  						csi_pixel_bit_depth = "16";
  						mode_type = "yuv";
  						pixel_phase = "uyvy";
  
  						active_w = "1920";
  						active_h = "1536";
  						readout_orientation = "0";
  						line_length = "1920";
  						inherent_gain = "1";
  						mclk_multiplier = "3.6864";
  						pix_clk_hz = "88473600";
  						serdes_pix_clk_hz = "375000000";
  
  						gain_factor = "10";
  						min_gain_val = "0"; /* dB */
  						max_gain_val = "300"; /* dB */
  						step_gain_val = "3"; /* 0.3 */
  						default_gain = "0";
  						min_hdr_ratio = "1";
  						max_hdr_ratio = "1";
  						framerate_factor = "1000000";
  						min_framerate = "30000000";
  						max_framerate = "30000000";
  						step_framerate = "1";
  						default_framerate = "30000000";
  						exposure_factor = "1000000";
  						min_exp_time = "59"; /*us, 2 lines*/
  						max_exp_time = "33333";
  						step_exp_time = "1";
  						default_exp_time = "33333";/* us */
  						embedded_metadata_height = "0";
  					};
  
  					mode3 {
  						mclk_khz = "24000";
  						num_lanes = "4";
  						tegra_sinterface = "serial_c";
  						vc_id = "2";
  						discontinuous_clk = "no";
  						dpcm_enable = "false";
  						cil_settletime = "0";
  						dynamic_pixel_bit_depth = "16";
  						csi_pixel_bit_depth = "16";
  						mode_type = "yuv";
  						pixel_phase = "uyvy";
  
  						active_w = "1600";
  						active_h = "1300";
  						readout_orientation = "0";
  						line_length = "1600";
  						inherent_gain = "1";
  						mclk_multiplier = "2.6";
  						pix_clk_hz = "62400000";
  						serdes_pix_clk_hz = "375000000";
  
  						gain_factor = "10";
  						min_gain_val = "0"; /* dB */
  						max_gain_val = "300"; /* dB */
  						step_gain_val = "3"; /* 0.3 */
  						default_gain = "0";
  						min_hdr_ratio = "1";
  						max_hdr_ratio = "1";
  						framerate_factor = "1000000";
  						min_framerate = "30000000";
  						max_framerate = "30000000";
  						step_framerate = "1";
  						default_framerate = "30000000";
  						exposure_factor = "1000000";
  						min_exp_time = "59"; /*us, 2 lines*/
  						max_exp_time = "33333";
  						step_exp_time = "1";
  						default_exp_time = "33333";/* us */
  						embedded_metadata_height = "0";
  					};
  
  					ports {
  						#address-cells = <1>;
  						#size-cells = <0>;
  						port@0 {
  							reg = <0>;
  							camera_out6: endpoint {
  								vc-id = <2>;
  								port-index = <2>;
  								bus-width = <4>;
  								remote-endpoint = <&csi_in6>;
  							};
  						};
  					};
  				};
  				
  				sensing_sensors_7 {
					status = "okay";
  					compatible = "sensing,gmsl2_sensor";
					clocks = <&bpmp_clks TEGRA234_CLK_EXTPERIPH1>,
							 <&bpmp_clks TEGRA234_CLK_EXTPERIPH1>;
					clock-names = "extperiph1", "pllp_grtba";
					mclk = "extperiph1";
  					reg = <0x2e>;
  
  					devnode = "video7";
  
  					/* Physical dimensions of sensor */
  					physical_w = "15.0";
  					physical_h = "12.5";
  					sensor_model = "gmsl2_sensor";
  
  					/* Defines number of frames to be dropped by driver internally after applying */
  					/* sensor crop settings. Some sensors send corrupt frames after applying */
  					/* crop co-ordinates */
  					post_crop_frame_drop = "0";
  
  					/* Convert Gain to unit of dB (decibel) befor passing to kernel driver */
  					use_decibel_gain = "true";
  
  					/* enable CID_SENSOR_MODE_ID for sensor modes selection */
  					use_sensor_mode_id = "false";
  
  					mode0 {
  						mclk_khz = "24000";
  						num_lanes = "4";
  						tegra_sinterface = "serial_c";
  						vc_id = "3";
  						discontinuous_clk = "no";
  						dpcm_enable = "false";
  						cil_settletime = "0";
  						dynamic_pixel_bit_depth = "16";
  						csi_pixel_bit_depth = "16";
  						mode_type = "yuv";
  						pixel_phase = "uyvy";
  
  						active_w = "2880";
  						active_h = "1860";
  						readout_orientation = "0";
  						line_length = "2880";
  						inherent_gain = "1";
  						mclk_multiplier = "6.696";
  						pix_clk_hz = "160704000";
  						serdes_pix_clk_hz = "375000000";
  
  						gain_factor = "10";
  						min_gain_val = "0"; /* dB */
  						max_gain_val = "300"; /* dB */
  						step_gain_val = "3"; /* 0.3 */
  						default_gain = "0";
  						min_hdr_ratio = "1";
  						max_hdr_ratio = "1";
  						framerate_factor = "1000000";
  						min_framerate = "30000000";
  						max_framerate = "30000000";
  						step_framerate = "1";
  						default_framerate = "30000000";
  						exposure_factor = "1000000";
  						min_exp_time = "59"; /*us, 2 lines*/
  						max_exp_time = "33333";
  						step_exp_time = "1";
  						default_exp_time = "33333";/* us */
  						embedded_metadata_height = "0";
  					};
  
  					mode1 {
  						mclk_khz = "24000";
  						num_lanes = "4";
  						tegra_sinterface = "serial_c";
  						vc_id = "3";
  						discontinuous_clk = "yes";
  						dpcm_enable = "false";
  						cil_settletime = "0";
  						dynamic_pixel_bit_depth = "16";
  						csi_pixel_bit_depth = "16";
  						mode_type = "yuv";
  						pixel_phase = "uyvy";
  
  						active_w = "3840";
  						active_h = "2160";
  						readout_orientation = "0";
  						line_length = "3840";
  						inherent_gain = "1";
  						mclk_multiplier = "10.368";
  						pix_clk_hz = "248832000";
  						serdes_pix_clk_hz = "600000000";
  
  						gain_factor = "10";
  						min_gain_val = "0"; /* dB */
  						max_gain_val = "300"; /* dB */
  						step_gain_val = "3"; /* 0.3 */
  						default_gain = "0";
  						min_hdr_ratio = "1";
  						max_hdr_ratio = "1";
  						framerate_factor = "1000000";
  						min_framerate = "30000000";
  						max_framerate = "30000000";
  						step_framerate = "1";
  						default_framerate = "30000000";
  						exposure_factor = "1000000";
  						min_exp_time = "59"; /*us, 2 lines*/
  						max_exp_time = "33333";
  						step_exp_time = "1";
  						default_exp_time = "33333";/* us */
  						embedded_metadata_height = "0";
  					};
  
  					mode2 {
  						mclk_khz = "24000";
  						num_lanes = "4";
  						tegra_sinterface = "serial_c";
  						vc_id = "3";
  						discontinuous_clk = "no";
  						dpcm_enable = "false";
  						cil_settletime = "0";
  						dynamic_pixel_bit_depth = "16";
  						csi_pixel_bit_depth = "16";
  						mode_type = "yuv";
  						pixel_phase = "uyvy";
  
  						active_w = "1920";
  						active_h = "1536";
  						readout_orientation = "0";
  						line_length = "1920";
  						inherent_gain = "1";
  						mclk_multiplier = "3.6864";
  						pix_clk_hz = "88473600";
  						serdes_pix_clk_hz = "375000000";
  
  						gain_factor = "10";
  						min_gain_val = "0"; /* dB */
  						max_gain_val = "300"; /* dB */
  						step_gain_val = "3"; /* 0.3 */
  						default_gain = "0";
  						min_hdr_ratio = "1";
  						max_hdr_ratio = "1";
  						framerate_factor = "1000000";
  						min_framerate = "30000000";
  						max_framerate = "30000000";
  						step_framerate = "1";
  						default_framerate = "30000000";
  						exposure_factor = "1000000";
  						min_exp_time = "59"; /*us, 2 lines*/
  						max_exp_time = "33333";
  						step_exp_time = "1";
  						default_exp_time = "33333";/* us */
  						embedded_metadata_height = "0";
  					};
  
  					mode3 {
  						mclk_khz = "24000";
  						num_lanes = "4";
  						tegra_sinterface = "serial_c";
  						vc_id = "3";
  						discontinuous_clk = "no";
  						dpcm_enable = "false";
  						cil_settletime = "0";
  						dynamic_pixel_bit_depth = "16";
  						csi_pixel_bit_depth = "16";
  						mode_type = "yuv";
  						pixel_phase = "uyvy";
  
  						active_w = "1600";
  						active_h = "1300";
  						readout_orientation = "0";
  						line_length = "1600";
  						inherent_gain = "1";
  						mclk_multiplier = "2.6";
  						pix_clk_hz = "62400000";
  						serdes_pix_clk_hz = "375000000";
  
  						gain_factor = "10";
  						min_gain_val = "0"; /* dB */
  						max_gain_val = "300"; /* dB */
  						step_gain_val = "3"; /* 0.3 */
  						default_gain = "0";
  						min_hdr_ratio = "1";
  						max_hdr_ratio = "1";
  						framerate_factor = "1000000";
  						min_framerate = "30000000";
  						max_framerate = "30000000";
  						step_framerate = "1";
  						default_framerate = "30000000";
  						exposure_factor = "1000000";
  						min_exp_time = "59"; /*us, 2 lines*/
  						max_exp_time = "33333";
  						step_exp_time = "1";
  						default_exp_time = "33333";/* us */
  						embedded_metadata_height = "0";
  					};
  
  					ports {
  						#address-cells = <1>;
  						#size-cells = <0>;
  						port@0 {
  							reg = <0>;
  							camera_out7: endpoint {
  								vc-id = <3>;
  								port-index = <2>;
  								bus-width = <4>;
  								remote-endpoint = <&csi_in7>;
  							};
  						};
  					};
  				};
	};

	//------------------------------

	
	i2c@c250000 {
		sensing_sensors_8 {
					status = "okay";
  					compatible = "sensing,gmsl2_sensor";
					clocks = <&bpmp_clks TEGRA234_CLK_EXTPERIPH1>,
							 <&bpmp_clks TEGRA234_CLK_EXTPERIPH1>;
					clock-names = "extperiph1", "pllp_grtba";
					mclk = "extperiph1";
  					reg = <0x3b>;
  
  					devnode = "video8";
  
  					/* Physical dimensions of sensor */
  					physical_w = "15.0";
  					physical_h = "12.5";
  					sensor_model = "gmsl2_sensor";
  
  					/* Defines number of frames to be dropped by driver internally after applying */
  					/* sensor crop settings. Some sensors send corrupt frames after applying */
  					/* crop co-ordinates */
  					post_crop_frame_drop = "0";
  
  					/* Convert Gain to unit of dB (decibel) befor passing to kernel driver */
  					use_decibel_gain = "true";
  
  					/* enable CID_SENSOR_MODE_ID for sensor modes selection */
  					use_sensor_mode_id = "false";
  
  					mode0 {
  						mclk_khz = "24000";
  						num_lanes = "4";
  						tegra_sinterface = "serial_e";
  						vc_id = "0";
  						discontinuous_clk = "no";
  						dpcm_enable = "false";
  						cil_settletime = "0";
  						dynamic_pixel_bit_depth = "16";
  						csi_pixel_bit_depth = "16";
  						mode_type = "yuv";
  						pixel_phase = "uyvy";
  
  						active_w = "2880";
  						active_h = "1860";
  						readout_orientation = "0";
  						line_length = "2880";
  						inherent_gain = "1";
  						mclk_multiplier = "6.696";
  						pix_clk_hz = "160704000";
  						serdes_pix_clk_hz = "375000000";
  
  						gain_factor = "10";
  						min_gain_val = "0"; /* dB */
  						max_gain_val = "300"; /* dB */
  						step_gain_val = "3"; /* 0.3 */
  						default_gain = "0";
  						min_hdr_ratio = "1";
  						max_hdr_ratio = "1";
  						framerate_factor = "1000000";
  						min_framerate = "30000000";
  						max_framerate = "30000000";
  						step_framerate = "1";
  						default_framerate = "30000000";
  						exposure_factor = "1000000";
  						min_exp_time = "59"; /*us, 2 lines*/
  						max_exp_time = "33333";
  						step_exp_time = "1";
  						default_exp_time = "33333";/* us */
  						embedded_metadata_height = "0";
  					};
  
  					mode1 {
  						mclk_khz = "24000";
  						num_lanes = "4";
  						tegra_sinterface = "serial_e";
  						vc_id = "0";
  						discontinuous_clk = "yes";
  						dpcm_enable = "false";
  						cil_settletime = "0";
  						dynamic_pixel_bit_depth = "16";
  						csi_pixel_bit_depth = "16";
  						mode_type = "yuv";
  						pixel_phase = "uyvy";
  
  						active_w = "3840";
  						active_h = "2160";
  						readout_orientation = "0";
  						line_length = "3840";
  						inherent_gain = "1";
  						mclk_multiplier = "10.368";
  						pix_clk_hz = "248832000";
  						serdes_pix_clk_hz = "600000000";
  
  						gain_factor = "10";
  						min_gain_val = "0"; /* dB */
  						max_gain_val = "300"; /* dB */
  						step_gain_val = "3"; /* 0.3 */
  						default_gain = "0";
  						min_hdr_ratio = "1";
  						max_hdr_ratio = "1";
  						framerate_factor = "1000000";
  						min_framerate = "30000000";
  						max_framerate = "30000000";
  						step_framerate = "1";
  						default_framerate = "30000000";
  						exposure_factor = "1000000";
  						min_exp_time = "59"; /*us, 2 lines*/
  						max_exp_time = "33333";
  						step_exp_time = "1";
  						default_exp_time = "33333";/* us */
  						embedded_metadata_height = "0";
  					};
  
  					mode2 {
  						mclk_khz = "24000";
  						num_lanes = "4";
  						tegra_sinterface = "serial_e";
  						vc_id = "0";
  						discontinuous_clk = "no";
  						dpcm_enable = "false";
  						cil_settletime = "0";
  						dynamic_pixel_bit_depth = "16";
  						csi_pixel_bit_depth = "16";
  						mode_type = "yuv";
  						pixel_phase = "uyvy";
  
  						active_w = "1920";
  						active_h = "1536";
  						readout_orientation = "0";
  						line_length = "1920";
  						inherent_gain = "1";
  						mclk_multiplier = "3.6864";
  						pix_clk_hz = "88473600";
  						serdes_pix_clk_hz = "375000000";
  
  						gain_factor = "10";
  						min_gain_val = "0"; /* dB */
  						max_gain_val = "300"; /* dB */
  						step_gain_val = "3"; /* 0.3 */
  						default_gain = "0";
  						min_hdr_ratio = "1";
  						max_hdr_ratio = "1";
  						framerate_factor = "1000000";
  						min_framerate = "30000000";
  						max_framerate = "30000000";
  						step_framerate = "1";
  						default_framerate = "30000000";
  						exposure_factor = "1000000";
  						min_exp_time = "59"; /*us, 2 lines*/
  						max_exp_time = "33333";
  						step_exp_time = "1";
  						default_exp_time = "33333";/* us */
  						embedded_metadata_height = "0";
  					};
  
  					mode3 {
  						mclk_khz = "24000";
  						num_lanes = "4";
  						tegra_sinterface = "serial_e";
  						vc_id = "0";
  						discontinuous_clk = "no";
  						dpcm_enable = "false";
  						cil_settletime = "0";
  						dynamic_pixel_bit_depth = "16";
  						csi_pixel_bit_depth = "16";
  						mode_type = "yuv";
  						pixel_phase = "uyvy";
  
  						active_w = "1600";
  						active_h = "1300";
  						readout_orientation = "0";
  						line_length = "1600";
  						inherent_gain = "1";
  						mclk_multiplier = "2.6";
  						pix_clk_hz = "62400000";
  						serdes_pix_clk_hz = "375000000";
  
  						gain_factor = "10";
  						min_gain_val = "0"; /* dB */
  						max_gain_val = "300"; /* dB */
  						step_gain_val = "3"; /* 0.3 */
  						default_gain = "0";
  						min_hdr_ratio = "1";
  						max_hdr_ratio = "1";
  						framerate_factor = "1000000";
  						min_framerate = "30000000";
  						max_framerate = "30000000";
  						step_framerate = "1";
  						default_framerate = "30000000";
  						exposure_factor = "1000000";
  						min_exp_time = "59"; /*us, 2 lines*/
  						max_exp_time = "33333";
  						step_exp_time = "1";
  						default_exp_time = "33333";/* us */
  						embedded_metadata_height = "0";
  					};
  
  					ports {
  						#address-cells = <1>;
  						#size-cells = <0>;
  						port@0 {
  							reg = <0>;
  							camera_out8: endpoint {
  								vc-id = <0>;
  								port-index = <6>; // workaround for SerDes 2&3 MIPI layout reversed
  								bus-width = <4>;
  								remote-endpoint = <&csi_in12>; // workaround for SerDes 2&3 MIPI layout reversed
  							};
  						};
  					};
  				};
      
  				sensing_sensors_9 {
					status = "okay";
  					compatible = "sensing,gmsl2_sensor";
					clocks = <&bpmp_clks TEGRA234_CLK_EXTPERIPH1>,
							 <&bpmp_clks TEGRA234_CLK_EXTPERIPH1>;
					clock-names = "extperiph1", "pllp_grtba";
					mclk = "extperiph1";
  					reg = <0x3c>;
  
  					devnode = "video9";
  
  					/* Physical dimensions of sensor */
  					physical_w = "15.0";
  					physical_h = "12.5";
  					sensor_model = "gmsl2_sensor";
  
  					/* Defines number of frames to be dropped by driver internally after applying */
  					/* sensor crop settings. Some sensors send corrupt frames after applying */
  					/* crop co-ordinates */
  					post_crop_frame_drop = "0";
  
  					/* Convert Gain to unit of dB (decibel) befor passing to kernel driver */
  					use_decibel_gain = "true";
  
  					/* enable CID_SENSOR_MODE_ID for sensor modes selection */
  					use_sensor_mode_id = "false";
  
  					mode0 {
  						mclk_khz = "24000";
  						num_lanes = "4";
  						tegra_sinterface = "serial_e";
  						vc_id = "1";
  						discontinuous_clk = "no";
  						dpcm_enable = "false";
  						cil_settletime = "0";
  						dynamic_pixel_bit_depth = "16";
  						csi_pixel_bit_depth = "16";
  						mode_type = "yuv";
  						pixel_phase = "uyvy";
  
  						active_w = "2880";
  						active_h = "1860";
  						readout_orientation = "0";
  						line_length = "2880";
  						inherent_gain = "1";
  						mclk_multiplier = "6.696";
  						pix_clk_hz = "160704000";
  						serdes_pix_clk_hz = "375000000";
  
  						gain_factor = "10";
  						min_gain_val = "0"; /* dB */
  						max_gain_val = "300"; /* dB */
  						step_gain_val = "3"; /* 0.3 */
  						default_gain = "0";
  						min_hdr_ratio = "1";
  						max_hdr_ratio = "1";
  						framerate_factor = "1000000";
  						min_framerate = "30000000";
  						max_framerate = "30000000";
  						step_framerate = "1";
  						default_framerate = "30000000";
  						exposure_factor = "1000000";
  						min_exp_time = "59"; /*us, 2 lines*/
  						max_exp_time = "33333";
  						step_exp_time = "1";
  						default_exp_time = "33333";/* us */
  						embedded_metadata_height = "0";
  					};
  
  					mode1 {
  						mclk_khz = "24000";
  						num_lanes = "4";
  						tegra_sinterface = "serial_e";
  						vc_id = "1";
  						discontinuous_clk = "yes";
  						dpcm_enable = "false";
  						cil_settletime = "0";
  						dynamic_pixel_bit_depth = "16";
  						csi_pixel_bit_depth = "16";
  						mode_type = "yuv";
  						pixel_phase = "uyvy";
  
  						active_w = "3840";
  						active_h = "2160";
  						readout_orientation = "0";
  						line_length = "3840";
  						inherent_gain = "1";
  						mclk_multiplier = "10.368";
  						pix_clk_hz = "248832000";
  						serdes_pix_clk_hz = "600000000";
  
  						gain_factor = "10";
  						min_gain_val = "0"; /* dB */
  						max_gain_val = "300"; /* dB */
  						step_gain_val = "3"; /* 0.3 */
  						default_gain = "0";
  						min_hdr_ratio = "1";
  						max_hdr_ratio = "1";
  						framerate_factor = "1000000";
  						min_framerate = "30000000";
  						max_framerate = "30000000";
  						step_framerate = "1";
  						default_framerate = "30000000";
  						exposure_factor = "1000000";
  						min_exp_time = "59"; /*us, 2 lines*/
  						max_exp_time = "33333";
  						step_exp_time = "1";
  						default_exp_time = "33333";/* us */
  						embedded_metadata_height = "0";
  					};
  
  					mode2 {
  						mclk_khz = "24000";
  						num_lanes = "4";
  						tegra_sinterface = "serial_e";
  						vc_id = "1";
  						discontinuous_clk = "no";
  						dpcm_enable = "false";
  						cil_settletime = "0";
  						dynamic_pixel_bit_depth = "16";
  						csi_pixel_bit_depth = "16";
  						mode_type = "yuv";
  						pixel_phase = "uyvy";
  
  						active_w = "1920";
  						active_h = "1536";
  						readout_orientation = "0";
  						line_length = "1920";
  						inherent_gain = "1";
  						mclk_multiplier = "3.6864";
  						pix_clk_hz = "88473600";
  						serdes_pix_clk_hz = "375000000";
  
  						gain_factor = "10";
  						min_gain_val = "0"; /* dB */
  						max_gain_val = "300"; /* dB */
  						step_gain_val = "3"; /* 0.3 */
  						default_gain = "0";
  						min_hdr_ratio = "1";
  						max_hdr_ratio = "1";
  						framerate_factor = "1000000";
  						min_framerate = "30000000";
  						max_framerate = "30000000";
  						step_framerate = "1";
  						default_framerate = "30000000";
  						exposure_factor = "1000000";
  						min_exp_time = "59"; /*us, 2 lines*/
  						max_exp_time = "33333";
  						step_exp_time = "1";
  						default_exp_time = "33333";/* us */
  						embedded_metadata_height = "0";
  					};
  
  					mode3 {
  						mclk_khz = "24000";
  						num_lanes = "4";
  						tegra_sinterface = "serial_e";
  						vc_id = "1";
  						discontinuous_clk = "no";
  						dpcm_enable = "false";
  						cil_settletime = "0";
  						dynamic_pixel_bit_depth = "16";
  						csi_pixel_bit_depth = "16";
  						mode_type = "yuv";
  						pixel_phase = "uyvy";
  
  						active_w = "1600";
  						active_h = "1300";
  						readout_orientation = "0";
  						line_length = "1600";
  						inherent_gain = "1";
  						mclk_multiplier = "2.6";
  						pix_clk_hz = "62400000";
  						serdes_pix_clk_hz = "375000000";
  
  						gain_factor = "10";
  						min_gain_val = "0"; /* dB */
  						max_gain_val = "300"; /* dB */
  						step_gain_val = "3"; /* 0.3 */
  						default_gain = "0";
  						min_hdr_ratio = "1";
  						max_hdr_ratio = "1";
  						framerate_factor = "1000000";
  						min_framerate = "30000000";
  						max_framerate = "30000000";
  						step_framerate = "1";
  						default_framerate = "30000000";
  						exposure_factor = "1000000";
  						min_exp_time = "59"; /*us, 2 lines*/
  						max_exp_time = "33333";
  						step_exp_time = "1";
  						default_exp_time = "33333";/* us */
  						embedded_metadata_height = "0";
  					};
  
  					ports {
  						#address-cells = <1>;
  						#size-cells = <0>;
  						port@0 {
  							reg = <0>;
  							camera_out9: endpoint {
  								vc-id = <1>;
  								port-index = <6>; // workaround for SerDes 2&3 MIPI layout reversed
  								bus-width = <4>;
  								remote-endpoint = <&csi_in13>; // workaround for SerDes 2&3 MIPI layout reversed
  							};
  						};
  					};
  				};
      
      
  				sensing_sensors_10 {
					status = "okay";
  					compatible = "sensing,gmsl2_sensor";
					clocks = <&bpmp_clks TEGRA234_CLK_EXTPERIPH1>,
							 <&bpmp_clks TEGRA234_CLK_EXTPERIPH1>;
					clock-names = "extperiph1", "pllp_grtba";
					mclk = "extperiph1";
  					reg = <0x3d>;
  
  					devnode = "video10";
  
  					/* Physical dimensions of sensor */
  					physical_w = "15.0";
  					physical_h = "12.5";
  					sensor_model = "gmsl2_sensor";
  
  					/* Defines number of frames to be dropped by driver internally after applying */
  					/* sensor crop settings. Some sensors send corrupt frames after applying */
  					/* crop co-ordinates */
  					post_crop_frame_drop = "0";
  
  					/* Convert Gain to unit of dB (decibel) befor passing to kernel driver */
  					use_decibel_gain = "true";
  
  					/* enable CID_SENSOR_MODE_ID for sensor modes selection */
  					use_sensor_mode_id = "false";
  
  					mode0 {
  						mclk_khz = "24000";
  						num_lanes = "4";
  						tegra_sinterface = "serial_e";
  						vc_id = "2";
  						discontinuous_clk = "no";
  						dpcm_enable = "false";
  						cil_settletime = "0";
  						dynamic_pixel_bit_depth = "16";
  						csi_pixel_bit_depth = "16";
  						mode_type = "yuv";
  						pixel_phase = "uyvy";
  
  						active_w = "2880";
  						active_h = "1860";
  						readout_orientation = "0";
  						line_length = "2880";
  						inherent_gain = "1";
  						mclk_multiplier = "6.696";
  						pix_clk_hz = "160704000";
  						serdes_pix_clk_hz = "375000000";
  
  						gain_factor = "10";
  						min_gain_val = "0"; /* dB */
  						max_gain_val = "300"; /* dB */
  						step_gain_val = "3"; /* 0.3 */
  						default_gain = "0";
  						min_hdr_ratio = "1";
  						max_hdr_ratio = "1";
  						framerate_factor = "1000000";
  						min_framerate = "30000000";
  						max_framerate = "30000000";
  						step_framerate = "1";
  						default_framerate = "30000000";
  						exposure_factor = "1000000";
  						min_exp_time = "59"; /*us, 2 lines*/
  						max_exp_time = "33333";
  						step_exp_time = "1";
  						default_exp_time = "33333";/* us */
  						embedded_metadata_height = "0";
  					};
  
  					mode1 {
  						mclk_khz = "24000";
  						num_lanes = "4";
  						tegra_sinterface = "serial_e";
  						vc_id = "2";
  						discontinuous_clk = "yes";
  						dpcm_enable = "false";
  						cil_settletime = "0";
  						dynamic_pixel_bit_depth = "16";
  						csi_pixel_bit_depth = "16";
  						mode_type = "yuv";
  						pixel_phase = "uyvy";
  
  						active_w = "3840";
  						active_h = "2160";
  						readout_orientation = "0";
  						line_length = "3840";
  						inherent_gain = "1";
  						mclk_multiplier = "10.368";
  						pix_clk_hz = "248832000";
  						serdes_pix_clk_hz = "600000000";
  
  						gain_factor = "10";
  						min_gain_val = "0"; /* dB */
  						max_gain_val = "300"; /* dB */
  						step_gain_val = "3"; /* 0.3 */
  						default_gain = "0";
  						min_hdr_ratio = "1";
  						max_hdr_ratio = "1";
  						framerate_factor = "1000000";
  						min_framerate = "30000000";
  						max_framerate = "30000000";
  						step_framerate = "1";
  						default_framerate = "30000000";
  						exposure_factor = "1000000";
  						min_exp_time = "59"; /*us, 2 lines*/
  						max_exp_time = "33333";
  						step_exp_time = "1";
  						default_exp_time = "33333";/* us */
  						embedded_metadata_height = "0";
  					};
  
  					mode2 {
  						mclk_khz = "24000";
  						num_lanes = "4";
  						tegra_sinterface = "serial_e";
  						vc_id = "2";
  						discontinuous_clk = "no";
  						dpcm_enable = "false";
  						cil_settletime = "0";
  						dynamic_pixel_bit_depth = "16";
  						csi_pixel_bit_depth = "16";
  						mode_type = "yuv";
  						pixel_phase = "uyvy";
  
  						active_w = "1920";
  						active_h = "1536";
  						readout_orientation = "0";
  						line_length = "1920";
  						inherent_gain = "1";
  						mclk_multiplier = "3.6864";
  						pix_clk_hz = "88473600";
  						serdes_pix_clk_hz = "375000000";
  
  						gain_factor = "10";
  						min_gain_val = "0"; /* dB */
  						max_gain_val = "300"; /* dB */
  						step_gain_val = "3"; /* 0.3 */
  						default_gain = "0";
  						min_hdr_ratio = "1";
  						max_hdr_ratio = "1";
  						framerate_factor = "1000000";
  						min_framerate = "30000000";
  						max_framerate = "30000000";
  						step_framerate = "1";
  						default_framerate = "30000000";
  						exposure_factor = "1000000";
  						min_exp_time = "59"; /*us, 2 lines*/
  						max_exp_time = "33333";
  						step_exp_time = "1";
  						default_exp_time = "33333";/* us */
  						embedded_metadata_height = "0";
  					};
  
  					mode3 {
  						mclk_khz = "24000";
  						num_lanes = "4";
  						tegra_sinterface = "serial_e";
  						vc_id = "2";
  						discontinuous_clk = "no";
  						dpcm_enable = "false";
  						cil_settletime = "0";
  						dynamic_pixel_bit_depth = "16";
  						csi_pixel_bit_depth = "16";
  						mode_type = "yuv";
  						pixel_phase = "uyvy";
  
  						active_w = "1600";
  						active_h = "1300";
  						readout_orientation = "0";
  						line_length = "1600";
  						inherent_gain = "1";
  						mclk_multiplier = "2.6";
  						pix_clk_hz = "62400000";
  						serdes_pix_clk_hz = "375000000";
  
  						gain_factor = "10";
  						min_gain_val = "0"; /* dB */
  						max_gain_val = "300"; /* dB */
  						step_gain_val = "3"; /* 0.3 */
  						default_gain = "0";
  						min_hdr_ratio = "1";
  						max_hdr_ratio = "1";
  						framerate_factor = "1000000";
  						min_framerate = "30000000";
  						max_framerate = "30000000";
  						step_framerate = "1";
  						default_framerate = "30000000";
  						exposure_factor = "1000000";
  						min_exp_time = "59"; /*us, 2 lines*/
  						max_exp_time = "33333";
  						step_exp_time = "1";
  						default_exp_time = "33333";/* us */
  						embedded_metadata_height = "0";
  					};
  
  					ports {
  						#address-cells = <1>;
  						#size-cells = <0>;
  						port@0 {
  							reg = <0>;
  							camera_out10: endpoint {
  								vc-id = <2>;
  								port-index = <6>; // workaround for SerDes 2&3 MIPI layout reversed
  								bus-width = <4>;
  								remote-endpoint = <&csi_in14>; // workaround for SerDes 2&3 MIPI layout reversed
  							};
  						};
  					};
  				};
      

  				sensing_sensors_11 {
					status = "okay";
  					compatible = "sensing,gmsl2_sensor";
					clocks = <&bpmp_clks TEGRA234_CLK_EXTPERIPH1>,
							 <&bpmp_clks TEGRA234_CLK_EXTPERIPH1>;
					clock-names = "extperiph1", "pllp_grtba";
					mclk = "extperiph1";
  					reg = <0x3e>;
  
  					devnode = "video11";
  
  					/* Physical dimensions of sensor */
  					physical_w = "15.0";
  					physical_h = "12.5";
  					sensor_model = "gmsl2_sensor";
  
  					/* Defines number of frames to be dropped by driver internally after applying */
  					/* sensor crop settings. Some sensors send corrupt frames after applying */
  					/* crop co-ordinates */
  					post_crop_frame_drop = "0";
  
  					/* Convert Gain to unit of dB (decibel) befor passing to kernel driver */
  					use_decibel_gain = "true";
  
  					/* enable CID_SENSOR_MODE_ID for sensor modes selection */
  					use_sensor_mode_id = "false";
  
  					mode0 {
  						mclk_khz = "24000";
  						num_lanes = "4";
  						tegra_sinterface = "serial_e";
  						vc_id = "3";
  						discontinuous_clk = "no";
  						dpcm_enable = "false";
  						cil_settletime = "0";
  						dynamic_pixel_bit_depth = "16";
  						csi_pixel_bit_depth = "16";
  						mode_type = "yuv";
  						pixel_phase = "uyvy";
  
  						active_w = "2880";
  						active_h = "1860";
  						readout_orientation = "0";
  						line_length = "2880";
  						inherent_gain = "1";
  						mclk_multiplier = "6.696";
  						pix_clk_hz = "160704000";
  						serdes_pix_clk_hz = "375000000";
  
  						gain_factor = "10";
  						min_gain_val = "0"; /* dB */
  						max_gain_val = "300"; /* dB */
  						step_gain_val = "3"; /* 0.3 */
  						default_gain = "0";
  						min_hdr_ratio = "1";
  						max_hdr_ratio = "1";
  						framerate_factor = "1000000";
  						min_framerate = "30000000";
  						max_framerate = "30000000";
  						step_framerate = "1";
  						default_framerate = "30000000";
  						exposure_factor = "1000000";
  						min_exp_time = "59"; /*us, 2 lines*/
  						max_exp_time = "33333";
  						step_exp_time = "1";
  						default_exp_time = "33333";/* us */
  						embedded_metadata_height = "0";
  					};
  
  					mode1 {
  						mclk_khz = "24000";
  						num_lanes = "4";
  						tegra_sinterface = "serial_e";
  						vc_id = "3";
  						discontinuous_clk = "yes";
  						dpcm_enable = "false";
  						cil_settletime = "0";
  						dynamic_pixel_bit_depth = "16";
  						csi_pixel_bit_depth = "16";
  						mode_type = "yuv";
  						pixel_phase = "uyvy";
  
  						active_w = "3840";
  						active_h = "2160";
  						readout_orientation = "0";
  						line_length = "3840";
  						inherent_gain = "1";
  						mclk_multiplier = "10.368";
  						pix_clk_hz = "248832000";
  						serdes_pix_clk_hz = "600000000";
  
  						gain_factor = "10";
  						min_gain_val = "0"; /* dB */
  						max_gain_val = "300"; /* dB */
  						step_gain_val = "3"; /* 0.3 */
  						default_gain = "0";
  						min_hdr_ratio = "1";
  						max_hdr_ratio = "1";
  						framerate_factor = "1000000";
  						min_framerate = "30000000";
  						max_framerate = "30000000";
  						step_framerate = "1";
  						default_framerate = "30000000";
  						exposure_factor = "1000000";
  						min_exp_time = "59"; /*us, 2 lines*/
  						max_exp_time = "33333";
  						step_exp_time = "1";
  						default_exp_time = "33333";/* us */
  						embedded_metadata_height = "0";
  					};
  
  					mode2 {
  						mclk_khz = "24000";
  						num_lanes = "4";
  						tegra_sinterface = "serial_e";
  						vc_id = "3";
  						discontinuous_clk = "no";
  						dpcm_enable = "false";
  						cil_settletime = "0";
  						dynamic_pixel_bit_depth = "16";
  						csi_pixel_bit_depth = "16";
  						mode_type = "yuv";
  						pixel_phase = "uyvy";
  
  						active_w = "1920";
  						active_h = "1536";
  						readout_orientation = "0";
  						line_length = "1920";
  						inherent_gain = "1";
  						mclk_multiplier = "3.6864";
  						pix_clk_hz = "88473600";
  						serdes_pix_clk_hz = "375000000";
  
  						gain_factor = "10";
  						min_gain_val = "0"; /* dB */
  						max_gain_val = "300"; /* dB */
  						step_gain_val = "3"; /* 0.3 */
  						default_gain = "0";
  						min_hdr_ratio = "1";
  						max_hdr_ratio = "1";
  						framerate_factor = "1000000";
  						min_framerate = "30000000";
  						max_framerate = "30000000";
  						step_framerate = "1";
  						default_framerate = "30000000";
  						exposure_factor = "1000000";
  						min_exp_time = "59"; /*us, 2 lines*/
  						max_exp_time = "33333";
  						step_exp_time = "1";
  						default_exp_time = "33333";/* us */
  						embedded_metadata_height = "0";
  					};
  
  					mode3 {
  						mclk_khz = "24000";
  						num_lanes = "4";
  						tegra_sinterface = "serial_e";
  						vc_id = "3";
  						discontinuous_clk = "no";
  						dpcm_enable = "false";
  						cil_settletime = "0";
  						dynamic_pixel_bit_depth = "16";
  						csi_pixel_bit_depth = "16";
  						mode_type = "yuv";
  						pixel_phase = "uyvy";
  
  						active_w = "1600";
  						active_h = "1300";
  						readout_orientation = "0";
  						line_length = "1600";
  						inherent_gain = "1";
  						mclk_multiplier = "2.6";
  						pix_clk_hz = "62400000";
  						serdes_pix_clk_hz = "375000000";
  
  						gain_factor = "10";
  						min_gain_val = "0"; /* dB */
  						max_gain_val = "300"; /* dB */
  						step_gain_val = "3"; /* 0.3 */
  						default_gain = "0";
  						min_hdr_ratio = "1";
  						max_hdr_ratio = "1";
  						framerate_factor = "1000000";
  						min_framerate = "30000000";
  						max_framerate = "30000000";
  						step_framerate = "1";
  						default_framerate = "30000000";
  						exposure_factor = "1000000";
  						min_exp_time = "59"; /*us, 2 lines*/
  						max_exp_time = "33333";
  						step_exp_time = "1";
  						default_exp_time = "33333";/* us */
  						embedded_metadata_height = "0";
  					};
  
  					ports {
  						#address-cells = <1>;
  						#size-cells = <0>;
  						port@0 {
  							reg = <0>;
  							camera_out11: endpoint {
  								vc-id = <3>;
  								port-index = <6>; // workaround for SerDes 2&3 MIPI layout reversed
  								bus-width = <4>;
  								remote-endpoint = <&csi_in15>; // workaround for SerDes 2&3 MIPI layout reversed
  							};
  						};
  					};
  				};
      
  				sensing_sensors_12 {
					status = "okay";
  					compatible = "sensing,gmsl2_sensor";
					clocks = <&bpmp_clks TEGRA234_CLK_EXTPERIPH1>,
							 <&bpmp_clks TEGRA234_CLK_EXTPERIPH1>;
					clock-names = "extperiph1", "pllp_grtba";
					mclk = "extperiph1";
  					reg = <0x5b>;
  
  					devnode = "video12";
  
  					/* Physical dimensions of sensor */
  					physical_w = "15.0";
  					physical_h = "12.5";
  					sensor_model = "gmsl2_sensor";
  
  					/* Defines number of frames to be dropped by driver internally after applying */
  					/* sensor crop settings. Some sensors send corrupt frames after applying */
  					/* crop co-ordinates */
  					post_crop_frame_drop = "0";
  
  					/* Convert Gain to unit of dB (decibel) befor passing to kernel driver */
  					use_decibel_gain = "true";
  
  					/* enable CID_SENSOR_MODE_ID for sensor modes selection */
  					use_sensor_mode_id = "false";
  
  					mode0 {
  						mclk_khz = "24000";
  						num_lanes = "4";
  						tegra_sinterface = "serial_g";
  						vc_id = "0";
  						discontinuous_clk = "no";
  						dpcm_enable = "false";
  						cil_settletime = "0";
  						dynamic_pixel_bit_depth = "16";
  						csi_pixel_bit_depth = "16";
  						mode_type = "yuv";
  						pixel_phase = "uyvy";
  
  						active_w = "2880";
  						active_h = "1860";
  						readout_orientation = "0";
  						line_length = "2880";
  						inherent_gain = "1";
  						mclk_multiplier = "6.696";
  						pix_clk_hz = "160704000";
  						serdes_pix_clk_hz = "375000000";
  
  						gain_factor = "10";
  						min_gain_val = "0"; /* dB */
  						max_gain_val = "300"; /* dB */
  						step_gain_val = "3"; /* 0.3 */
  						default_gain = "0";
  						min_hdr_ratio = "1";
  						max_hdr_ratio = "1";
  						framerate_factor = "1000000";
  						min_framerate = "30000000";
  						max_framerate = "30000000";
  						step_framerate = "1";
  						default_framerate = "30000000";
  						exposure_factor = "1000000";
  						min_exp_time = "59"; /*us, 2 lines*/
  						max_exp_time = "33333";
  						step_exp_time = "1";
  						default_exp_time = "33333";/* us */
  						embedded_metadata_height = "0";
  					};
  
  					mode1 {
  						mclk_khz = "24000";
  						num_lanes = "4";
  						tegra_sinterface = "serial_g";
  						vc_id = "0";
  						discontinuous_clk = "yes";
  						dpcm_enable = "false";
  						cil_settletime = "0";
  						dynamic_pixel_bit_depth = "16";
  						csi_pixel_bit_depth = "16";
  						mode_type = "yuv";
  						pixel_phase = "uyvy";
  
  						active_w = "3840";
  						active_h = "2160";
  						readout_orientation = "0";
  						line_length = "3840";
  						inherent_gain = "1";
  						mclk_multiplier = "10.368";
  						pix_clk_hz = "248832000";
  						serdes_pix_clk_hz = "600000000";
  
  						gain_factor = "10";
  						min_gain_val = "0"; /* dB */
  						max_gain_val = "300"; /* dB */
  						step_gain_val = "3"; /* 0.3 */
  						default_gain = "0";
  						min_hdr_ratio = "1";
  						max_hdr_ratio = "1";
  						framerate_factor = "1000000";
  						min_framerate = "30000000";
  						max_framerate = "30000000";
  						step_framerate = "1";
  						default_framerate = "30000000";
  						exposure_factor = "1000000";
  						min_exp_time = "59"; /*us, 2 lines*/
  						max_exp_time = "33333";
  						step_exp_time = "1";
  						default_exp_time = "33333";/* us */
  						embedded_metadata_height = "0";
  					};
  
  					mode2 {
  						mclk_khz = "24000";
  						num_lanes = "4";
  						tegra_sinterface = "serial_g";
  						vc_id = "0";
  						discontinuous_clk = "no";
  						dpcm_enable = "false";
  						cil_settletime = "0";
  						dynamic_pixel_bit_depth = "16";
  						csi_pixel_bit_depth = "16";
  						mode_type = "yuv";
  						pixel_phase = "uyvy";
  
  						active_w = "1920";
  						active_h = "1536";
  						readout_orientation = "0";
  						line_length = "1920";
  						inherent_gain = "1";
  						mclk_multiplier = "3.6864";
  						pix_clk_hz = "88473600";
  						serdes_pix_clk_hz = "375000000";
  
  						gain_factor = "10";
  						min_gain_val = "0"; /* dB */
  						max_gain_val = "300"; /* dB */
  						step_gain_val = "3"; /* 0.3 */
  						default_gain = "0";
  						min_hdr_ratio = "1";
  						max_hdr_ratio = "1";
  						framerate_factor = "1000000";
  						min_framerate = "30000000";
  						max_framerate = "30000000";
  						step_framerate = "1";
  						default_framerate = "30000000";
  						exposure_factor = "1000000";
  						min_exp_time = "59"; /*us, 2 lines*/
  						max_exp_time = "33333";
  						step_exp_time = "1";
  						default_exp_time = "33333";/* us */
  						embedded_metadata_height = "0";
  					};
  
  					mode3 {
  						mclk_khz = "24000";
  						num_lanes = "4";
  						tegra_sinterface = "serial_g";
  						vc_id = "0";
  						discontinuous_clk = "no";
  						dpcm_enable = "false";
  						cil_settletime = "0";
  						dynamic_pixel_bit_depth = "16";
  						csi_pixel_bit_depth = "16";
  						mode_type = "yuv";
  						pixel_phase = "uyvy";
  
  						active_w = "1600";
  						active_h = "1300";
  						readout_orientation = "0";
  						line_length = "1600";
  						inherent_gain = "1";
  						mclk_multiplier = "2.6";
  						pix_clk_hz = "62400000";
  						serdes_pix_clk_hz = "375000000";
  
  						gain_factor = "10";
  						min_gain_val = "0"; /* dB */
  						max_gain_val = "300"; /* dB */
  						step_gain_val = "3"; /* 0.3 */
  						default_gain = "0";
  						min_hdr_ratio = "1";
  						max_hdr_ratio = "1";
  						framerate_factor = "1000000";
  						min_framerate = "30000000";
  						max_framerate = "30000000";
  						step_framerate = "1";
  						default_framerate = "30000000";
  						exposure_factor = "1000000";
  						min_exp_time = "59"; /*us, 2 lines*/
  						max_exp_time = "33333";
  						step_exp_time = "1";
  						default_exp_time = "33333";/* us */
  						embedded_metadata_height = "0";
  					};
  
  					ports {
  						#address-cells = <1>;
  						#size-cells = <0>;
  						port@0 {
  							reg = <0>;
  							camera_out12: endpoint {
  								vc-id = <0>;
  								port-index = <4>; // workaround for SerDes 2&3 MIPI layout reversed
  								bus-width = <4>;
  								remote-endpoint = <&csi_in8>; // workaround for SerDes 2&3 MIPI layout reversed
  							};
  						};
  					};
  				};
      
  				sensing_sensors_13 {
					status = "okay";
  					compatible = "sensing,gmsl2_sensor";
					clocks = <&bpmp_clks TEGRA234_CLK_EXTPERIPH1>,
							 <&bpmp_clks TEGRA234_CLK_EXTPERIPH1>;
					clock-names = "extperiph1", "pllp_grtba";
					mclk = "extperiph1";
  					reg = <0x5c>;
  
  					devnode = "video13";
  
  					/* Physical dimensions of sensor */
  					physical_w = "15.0";
  					physical_h = "12.5";
  					sensor_model = "gmsl2_sensor";
  
  					/* Defines number of frames to be dropped by driver internally after applying */
  					/* sensor crop settings. Some sensors send corrupt frames after applying */
  					/* crop co-ordinates */
  					post_crop_frame_drop = "0";
  
  					/* Convert Gain to unit of dB (decibel) befor passing to kernel driver */
  					use_decibel_gain = "true";
  
  					/* enable CID_SENSOR_MODE_ID for sensor modes selection */
  					use_sensor_mode_id = "false";
  
  					mode0 {
  						mclk_khz = "24000";
  						num_lanes = "4";
  						tegra_sinterface = "serial_g";
  						vc_id = "1";
  						discontinuous_clk = "no";
  						dpcm_enable = "false";
  						cil_settletime = "0";
  						dynamic_pixel_bit_depth = "16";
  						csi_pixel_bit_depth = "16";
  						mode_type = "yuv";
  						pixel_phase = "uyvy";
  
  						active_w = "2880";
  						active_h = "1860";
  						readout_orientation = "0";
  						line_length = "2880";
  						inherent_gain = "1";
  						mclk_multiplier = "6.696";
  						pix_clk_hz = "160704000";
  						serdes_pix_clk_hz = "375000000";
  
  						gain_factor = "10";
  						min_gain_val = "0"; /* dB */
  						max_gain_val = "300"; /* dB */
  						step_gain_val = "3"; /* 0.3 */
  						default_gain = "0";
  						min_hdr_ratio = "1";
  						max_hdr_ratio = "1";
  						framerate_factor = "1000000";
  						min_framerate = "30000000";
  						max_framerate = "30000000";
  						step_framerate = "1";
  						default_framerate = "30000000";
  						exposure_factor = "1000000";
  						min_exp_time = "59"; /*us, 2 lines*/
  						max_exp_time = "33333";
  						step_exp_time = "1";
  						default_exp_time = "33333";/* us */
  						embedded_metadata_height = "0";
  					};
  
  					mode1 {
  						mclk_khz = "24000";
  						num_lanes = "4";
  						tegra_sinterface = "serial_g";
  						vc_id = "1";
  						discontinuous_clk = "yes";
  						dpcm_enable = "false";
  						cil_settletime = "0";
  						dynamic_pixel_bit_depth = "16";
  						csi_pixel_bit_depth = "16";
  						mode_type = "yuv";
  						pixel_phase = "uyvy";
  
  						active_w = "3840";
  						active_h = "2160";
  						readout_orientation = "0";
  						line_length = "3840";
  						inherent_gain = "1";
  						mclk_multiplier = "10.368";
  						pix_clk_hz = "248832000";
  						serdes_pix_clk_hz = "600000000";
  
  						gain_factor = "10";
  						min_gain_val = "0"; /* dB */
  						max_gain_val = "300"; /* dB */
  						step_gain_val = "3"; /* 0.3 */
  						default_gain = "0";
  						min_hdr_ratio = "1";
  						max_hdr_ratio = "1";
  						framerate_factor = "1000000";
  						min_framerate = "30000000";
  						max_framerate = "30000000";
  						step_framerate = "1";
  						default_framerate = "30000000";
  						exposure_factor = "1000000";
  						min_exp_time = "59"; /*us, 2 lines*/
  						max_exp_time = "33333";
  						step_exp_time = "1";
  						default_exp_time = "33333";/* us */
  						embedded_metadata_height = "0";
  					};
  
  					mode2 {
  						mclk_khz = "24000";
  						num_lanes = "4";
  						tegra_sinterface = "serial_g";
  						vc_id = "1";
  						discontinuous_clk = "no";
  						dpcm_enable = "false";
  						cil_settletime = "0";
  						dynamic_pixel_bit_depth = "16";
  						csi_pixel_bit_depth = "16";
  						mode_type = "yuv";
  						pixel_phase = "uyvy";
  
  						active_w = "1920";
  						active_h = "1536";
  						readout_orientation = "0";
  						line_length = "1920";
  						inherent_gain = "1";
  						mclk_multiplier = "3.6864";
  						pix_clk_hz = "88473600";
  						serdes_pix_clk_hz = "375000000";
  
  						gain_factor = "10";
  						min_gain_val = "0"; /* dB */
  						max_gain_val = "300"; /* dB */
  						step_gain_val = "3"; /* 0.3 */
  						default_gain = "0";
  						min_hdr_ratio = "1";
  						max_hdr_ratio = "1";
  						framerate_factor = "1000000";
  						min_framerate = "30000000";
  						max_framerate = "30000000";
  						step_framerate = "1";
  						default_framerate = "30000000";
  						exposure_factor = "1000000";
  						min_exp_time = "59"; /*us, 2 lines*/
  						max_exp_time = "33333";
  						step_exp_time = "1";
  						default_exp_time = "33333";/* us */
  						embedded_metadata_height = "0";
  					};
  
  					mode3 {
  						mclk_khz = "24000";
  						num_lanes = "4";
  						tegra_sinterface = "serial_g";
  						vc_id = "1";
  						discontinuous_clk = "no";
  						dpcm_enable = "false";
  						cil_settletime = "0";
  						dynamic_pixel_bit_depth = "16";
  						csi_pixel_bit_depth = "16";
  						mode_type = "yuv";
  						pixel_phase = "uyvy";
  
  						active_w = "1600";
  						active_h = "1300";
  						readout_orientation = "0";
  						line_length = "1600";
  						inherent_gain = "1";
  						mclk_multiplier = "2.6";
  						pix_clk_hz = "62400000";
  						serdes_pix_clk_hz = "375000000";
  
  						gain_factor = "10";
  						min_gain_val = "0"; /* dB */
  						max_gain_val = "300"; /* dB */
  						step_gain_val = "3"; /* 0.3 */
  						default_gain = "0";
  						min_hdr_ratio = "1";
  						max_hdr_ratio = "1";
  						framerate_factor = "1000000";
  						min_framerate = "30000000";
  						max_framerate = "30000000";
  						step_framerate = "1";
  						default_framerate = "30000000";
  						exposure_factor = "1000000";
  						min_exp_time = "59"; /*us, 2 lines*/
  						max_exp_time = "33333";
  						step_exp_time = "1";
  						default_exp_time = "33333";/* us */
  						embedded_metadata_height = "0";
  					};
  
  					ports {
  						#address-cells = <1>;
  						#size-cells = <0>;
  						port@0 {
  							reg = <0>;
  							camera_out13: endpoint {
  								vc-id = <1>;
  								port-index = <4>; // workaround for SerDes 2&3 MIPI layout reversed
  								bus-width = <4>;
  								remote-endpoint = <&csi_in9>; // workaround for SerDes 2&3 MIPI layout reversed
  							};
  						};
  					};
  				};
      
  				sensing_sensors_14 {
					status = "okay";
  					compatible = "sensing,gmsl2_sensor";
					clocks = <&bpmp_clks TEGRA234_CLK_EXTPERIPH1>,
							 <&bpmp_clks TEGRA234_CLK_EXTPERIPH1>;
					clock-names = "extperiph1", "pllp_grtba";
					mclk = "extperiph1";
  					reg = <0x5d>;
  
  					devnode = "video14";
  
  					/* Physical dimensions of sensor */
  					physical_w = "15.0";
  					physical_h = "12.5";
  					sensor_model = "gmsl2_sensor";
  
  					/* Defines number of frames to be dropped by driver internally after applying */
  					/* sensor crop settings. Some sensors send corrupt frames after applying */
  					/* crop co-ordinates */
  					post_crop_frame_drop = "0";
  
  					/* Convert Gain to unit of dB (decibel) befor passing to kernel driver */
  					use_decibel_gain = "true";
  
  					/* enable CID_SENSOR_MODE_ID for sensor modes selection */
  					use_sensor_mode_id = "false";
  
  					mode0 {
  						mclk_khz = "24000";
  						num_lanes = "4";
  						tegra_sinterface = "serial_g";
  						vc_id = "2";
  						discontinuous_clk = "no";
  						dpcm_enable = "false";
  						cil_settletime = "0";
  						dynamic_pixel_bit_depth = "16";
  						csi_pixel_bit_depth = "16";
  						mode_type = "yuv";
  						pixel_phase = "uyvy";
  
  						active_w = "2880";
  						active_h = "1860";
  						readout_orientation = "0";
  						line_length = "2880";
  						inherent_gain = "1";
  						mclk_multiplier = "6.696";
  						pix_clk_hz = "160704000";
  						serdes_pix_clk_hz = "375000000";
  
  						gain_factor = "10";
  						min_gain_val = "0"; /* dB */
  						max_gain_val = "300"; /* dB */
  						step_gain_val = "3"; /* 0.3 */
  						default_gain = "0";
  						min_hdr_ratio = "1";
  						max_hdr_ratio = "1";
  						framerate_factor = "1000000";
  						min_framerate = "30000000";
  						max_framerate = "30000000";
  						step_framerate = "1";
  						default_framerate = "30000000";
  						exposure_factor = "1000000";
  						min_exp_time = "59"; /*us, 2 lines*/
  						max_exp_time = "33333";
  						step_exp_time = "1";
  						default_exp_time = "33333";/* us */
  						embedded_metadata_height = "0";
  					};
  
  					mode1 {
  						mclk_khz = "24000";
  						num_lanes = "4";
  						tegra_sinterface = "serial_g";
  						vc_id = "2";
  						discontinuous_clk = "yes";
  						dpcm_enable = "false";
  						cil_settletime = "0";
  						dynamic_pixel_bit_depth = "16";
  						csi_pixel_bit_depth = "16";
  						mode_type = "yuv";
  						pixel_phase = "uyvy";
  
  						active_w = "3840";
  						active_h = "2160";
  						readout_orientation = "0";
  						line_length = "3840";
  						inherent_gain = "1";
  						mclk_multiplier = "10.368";
  						pix_clk_hz = "248832000";
  						serdes_pix_clk_hz = "600000000";
  
  						gain_factor = "10";
  						min_gain_val = "0"; /* dB */
  						max_gain_val = "300"; /* dB */
  						step_gain_val = "3"; /* 0.3 */
  						default_gain = "0";
  						min_hdr_ratio = "1";
  						max_hdr_ratio = "1";
  						framerate_factor = "1000000";
  						min_framerate = "30000000";
  						max_framerate = "30000000";
  						step_framerate = "1";
  						default_framerate = "30000000";
  						exposure_factor = "1000000";
  						min_exp_time = "59"; /*us, 2 lines*/
  						max_exp_time = "33333";
  						step_exp_time = "1";
  						default_exp_time = "33333";/* us */
  						embedded_metadata_height = "0";
  					};
  
  					mode2 {
  						mclk_khz = "24000";
  						num_lanes = "4";
  						tegra_sinterface = "serial_g";
  						vc_id = "2";
  						discontinuous_clk = "no";
  						dpcm_enable = "false";
  						cil_settletime = "0";
  						dynamic_pixel_bit_depth = "16";
  						csi_pixel_bit_depth = "16";
  						mode_type = "yuv";
  						pixel_phase = "uyvy";
  
  						active_w = "1920";
  						active_h = "1536";
  						readout_orientation = "0";
  						line_length = "1920";
  						inherent_gain = "1";
  						mclk_multiplier = "3.6864";
  						pix_clk_hz = "88473600";
  						serdes_pix_clk_hz = "375000000";
  
  						gain_factor = "10";
  						min_gain_val = "0"; /* dB */
  						max_gain_val = "300"; /* dB */
  						step_gain_val = "3"; /* 0.3 */
  						default_gain = "0";
  						min_hdr_ratio = "1";
  						max_hdr_ratio = "1";
  						framerate_factor = "1000000";
  						min_framerate = "30000000";
  						max_framerate = "30000000";
  						step_framerate = "1";
  						default_framerate = "30000000";
  						exposure_factor = "1000000";
  						min_exp_time = "59"; /*us, 2 lines*/
  						max_exp_time = "33333";
  						step_exp_time = "1";
  						default_exp_time = "33333";/* us */
  						embedded_metadata_height = "0";
  					};
  
  					mode3 {
  						mclk_khz = "24000";
  						num_lanes = "4";
  						tegra_sinterface = "serial_g";
  						vc_id = "2";
  						discontinuous_clk = "no";
  						dpcm_enable = "false";
  						cil_settletime = "0";
  						dynamic_pixel_bit_depth = "16";
  						csi_pixel_bit_depth = "16";
  						mode_type = "yuv";
  						pixel_phase = "uyvy";
  
  						active_w = "1600";
  						active_h = "1300";
  						readout_orientation = "0";
  						line_length = "1600";
  						inherent_gain = "1";
  						mclk_multiplier = "2.6";
  						pix_clk_hz = "62400000";
  						serdes_pix_clk_hz = "375000000";
  
  						gain_factor = "10";
  						min_gain_val = "0"; /* dB */
  						max_gain_val = "300"; /* dB */
  						step_gain_val = "3"; /* 0.3 */
  						default_gain = "0";
  						min_hdr_ratio = "1";
  						max_hdr_ratio = "1";
  						framerate_factor = "1000000";
  						min_framerate = "30000000";
  						max_framerate = "30000000";
  						step_framerate = "1";
  						default_framerate = "30000000";
  						exposure_factor = "1000000";
  						min_exp_time = "59"; /*us, 2 lines*/
  						max_exp_time = "33333";
  						step_exp_time = "1";
  						default_exp_time = "33333";/* us */
  						embedded_metadata_height = "0";
  					};
  
  					ports {
  						#address-cells = <1>;
  						#size-cells = <0>;
  						port@0 {
  							reg = <0>;
  							camera_out14: endpoint {
  								vc-id = <2>;
  								port-index = <4>; // workaround for SerDes 2&3 MIPI layout reversed
  								bus-width = <4>;
  								remote-endpoint = <&csi_in10>; // workaround for SerDes 2&3 MIPI layout reversed
  							};
  						};
  					};
  				};
      
  				sensing_sensors_15 {
					status = "okay";
  					compatible = "sensing,gmsl2_sensor";
					clocks = <&bpmp_clks TEGRA234_CLK_EXTPERIPH1>,
							 <&bpmp_clks TEGRA234_CLK_EXTPERIPH1>;
					clock-names = "extperiph1", "pllp_grtba";
					mclk = "extperiph1";
  					reg = <0x5e>;
  
  					devnode = "video15";
  
  					/* Physical dimensions of sensor */
  					physical_w = "15.0";
  					physical_h = "12.5";
  					sensor_model = "gmsl2_sensor";
  
  					/* Defines number of frames to be dropped by driver internally after applying */
  					/* sensor crop settings. Some sensors send corrupt frames after applying */
  					/* crop co-ordinates */
  					post_crop_frame_drop = "0";
  
  					/* Convert Gain to unit of dB (decibel) befor passing to kernel driver */
  					use_decibel_gain = "true";
  
  					/* enable CID_SENSOR_MODE_ID for sensor modes selection */
  					use_sensor_mode_id = "false";
  
  					mode0 {
  						mclk_khz = "24000";
  						num_lanes = "4";
  						tegra_sinterface = "serial_g";
  						vc_id = "3";
  						discontinuous_clk = "no";
  						dpcm_enable = "false";
  						cil_settletime = "0";
  						dynamic_pixel_bit_depth = "16";
  						csi_pixel_bit_depth = "16";
  						mode_type = "yuv";
  						pixel_phase = "uyvy";
  
  						active_w = "2880";
  						active_h = "1860";
  						readout_orientation = "0";
  						line_length = "2880";
  						inherent_gain = "1";
  						mclk_multiplier = "6.696";
  						pix_clk_hz = "160704000";
  						serdes_pix_clk_hz = "375000000";
  
  						gain_factor = "10";
  						min_gain_val = "0"; /* dB */
  						max_gain_val = "300"; /* dB */
  						step_gain_val = "3"; /* 0.3 */
  						default_gain = "0";
  						min_hdr_ratio = "1";
  						max_hdr_ratio = "1";
  						framerate_factor = "1000000";
  						min_framerate = "30000000";
  						max_framerate = "30000000";
  						step_framerate = "1";
  						default_framerate = "30000000";
  						exposure_factor = "1000000";
  						min_exp_time = "59"; /*us, 2 lines*/
  						max_exp_time = "33333";
  						step_exp_time = "1";
  						default_exp_time = "33333";/* us */
  						embedded_metadata_height = "0";
  					};
  
  					mode1 {
  						mclk_khz = "24000";
  						num_lanes = "4";
  						tegra_sinterface = "serial_g";
  						vc_id = "3";
  						discontinuous_clk = "yes";
  						dpcm_enable = "false";
  						cil_settletime = "0";
  						dynamic_pixel_bit_depth = "16";
  						csi_pixel_bit_depth = "16";
  						mode_type = "yuv";
  						pixel_phase = "uyvy";
  
  						active_w = "3840";
  						active_h = "2160";
  						readout_orientation = "0";
  						line_length = "3840";
  						inherent_gain = "1";
  						mclk_multiplier = "10.368";
  						pix_clk_hz = "248832000";
  						serdes_pix_clk_hz = "600000000";
  
  						gain_factor = "10";
  						min_gain_val = "0"; /* dB */
  						max_gain_val = "300"; /* dB */
  						step_gain_val = "3"; /* 0.3 */
  						default_gain = "0";
  						min_hdr_ratio = "1";
  						max_hdr_ratio = "1";
  						framerate_factor = "1000000";
  						min_framerate = "30000000";
  						max_framerate = "30000000";
  						step_framerate = "1";
  						default_framerate = "30000000";
  						exposure_factor = "1000000";
  						min_exp_time = "59"; /*us, 2 lines*/
  						max_exp_time = "33333";
  						step_exp_time = "1";
  						default_exp_time = "33333";/* us */
  						embedded_metadata_height = "0";
  					};
  
  					mode2 {
  						mclk_khz = "24000";
  						num_lanes = "4";
  						tegra_sinterface = "serial_g";
  						vc_id = "3";
  						discontinuous_clk = "no";
  						dpcm_enable = "false";
  						cil_settletime = "0";
  						dynamic_pixel_bit_depth = "16";
  						csi_pixel_bit_depth = "16";
  						mode_type = "yuv";
  						pixel_phase = "uyvy";
  
  						active_w = "1920";
  						active_h = "1536";
  						readout_orientation = "0";
  						line_length = "1920";
  						inherent_gain = "1";
  						mclk_multiplier = "3.6864";
  						pix_clk_hz = "88473600";
  						serdes_pix_clk_hz = "375000000";
  
  						gain_factor = "10";
  						min_gain_val = "0"; /* dB */
  						max_gain_val = "300"; /* dB */
  						step_gain_val = "3"; /* 0.3 */
  						default_gain = "0";
  						min_hdr_ratio = "1";
  						max_hdr_ratio = "1";
  						framerate_factor = "1000000";
  						min_framerate = "30000000";
  						max_framerate = "30000000";
  						step_framerate = "1";
  						default_framerate = "30000000";
  						exposure_factor = "1000000";
  						min_exp_time = "59"; /*us, 2 lines*/
  						max_exp_time = "33333";
  						step_exp_time = "1";
  						default_exp_time = "33333";/* us */
  						embedded_metadata_height = "0";
  					};
  
  					mode3 {
  						mclk_khz = "24000";
  						num_lanes = "4";
  						tegra_sinterface = "serial_g";
  						vc_id = "3";
  						discontinuous_clk = "no";
  						dpcm_enable = "false";
  						cil_settletime = "0";
  						dynamic_pixel_bit_depth = "16";
  						csi_pixel_bit_depth = "16";
  						mode_type = "yuv";
  						pixel_phase = "uyvy";
  
  						active_w = "1600";
  						active_h = "1300";
  						readout_orientation = "0";
  						line_length = "1600";
  						inherent_gain = "1";
  						mclk_multiplier = "2.6";
  						pix_clk_hz = "62400000";
  						serdes_pix_clk_hz = "375000000";
  
  						gain_factor = "10";
  						min_gain_val = "0"; /* dB */
  						max_gain_val = "300"; /* dB */
  						step_gain_val = "3"; /* 0.3 */
  						default_gain = "0";
  						min_hdr_ratio = "1";
  						max_hdr_ratio = "1";
  						framerate_factor = "1000000";
  						min_framerate = "30000000";
  						max_framerate = "30000000";
  						step_framerate = "1";
  						default_framerate = "30000000";
  						exposure_factor = "1000000";
  						min_exp_time = "59"; /*us, 2 lines*/
  						max_exp_time = "33333";
  						step_exp_time = "1";
  						default_exp_time = "33333";/* us */
  						embedded_metadata_height = "0";
  					};
  
  					ports {
  						#address-cells = <1>;
  						#size-cells = <0>;
  						port@0 {
  							reg = <0>;
  							camera_out15: endpoint {
  								vc-id = <3>;
  								port-index = <4>; // workaround for SerDes 2&3 MIPI layout reversed
  								bus-width = <4>;
  								remote-endpoint = <&csi_in11>; // workaround for SerDes 2&3 MIPI layout reversed
  							};
  						};
  					};
  				};
	};

	//------------------------------


	tegra-camera-platform {
          compatible = "nvidia, tegra-camera-platform";
          status = "okay";
		  num_csi_lanes = <4>;
		  max_lane_speed = <2500000>;
		  min_bits_per_pixel = <10>;
		  vi_peak_byte_per_pixel = <2>;
		  vi_bw_margin_pct = <25>;
		  max_pixel_rate = <750000>;
		  isp_peak_byte_per_pixel = <5>;
		  isp_bw_margin_pct = <25>;

          modules {
            camera_module0: module0 {
              status = "okay";
              badge = "sensing_sensors_0";
              position = "0";
              orientation = "1";
              drivernode0 {
                status = "okay";
                pcl_id = "v4l2_sensor";
                devname = "sensing_sensors_0";
                proc-device-tree = "/proc/device-tree/i2c@3180000/sensing_sensors_0";
              };
            };

            camera_module1: module1 {
              status = "okay";
              badge = "sensing_sensors_1";
              position = "1";
              orientation = "1";
              drivernode0 {
                status = "okay";
                pcl_id = "v4l2_sensor";
                devname = "sensing_sensors_1";
                proc-device-tree = "/proc/device-tree/i2c@3180000/sensing_sensors_1";
              };
            };

            camera_module2: module2 {
              status = "okay";
              badge = "sensing_sensors_2";
              position = "2";
              orientation = "1";
              drivernode0 {
                status = "okay";
                pcl_id = "v4l2_sensor";
                devname = "sensing_sensors_2";
                proc-device-tree = "/proc/device-tree/i2c@3180000/sensing_sensors_2";
              };
            };

            camera_module3: module3 {
              status = "okay";
              badge = "sensing_sensors_3";
              position = "3";
              orientation = "1";
              drivernode0 {
                status = "okay";
                pcl_id = "v4l2_sensor";
                devname = "sensing_sensors_3";
                proc-device-tree = "/proc/device-tree/i2c@3180000/sensing_sensors_3";
              };
            };

            camera_module4: module4 {
              status = "okay";
              badge = "sensing_sensors_4";
              position = "4";
              orientation = "1";
              drivernode0 {
                status = "okay";
                pcl_id = "v4l2_sensor";
                devname = "sensing_sensors_4";
                proc-device-tree = "/proc/device-tree/i2c@3180000/sensing_sensors_4";
              };
            };

            camera_module5: module5 {
              status = "okay";
              badge = "sensing_sensors_5";
              position = "5";
              orientation = "1";
              drivernode0 {
                status = "okay";
                pcl_id = "v4l2_sensor";
                devname = "sensing_sensors_5";
                proc-device-tree = "/proc/device-tree/i2c@3180000/sensing_sensors_5";
              };
            };

            camera_module6: module6 {
              status = "okay";
              badge = "sensing_sensors_6";
              position = "6";
              orientation = "1";
              drivernode0 {
                status = "okay";
                pcl_id = "v4l2_sensor";
                devname = "sensing_sensors_6";
                proc-device-tree = "/proc/device-tree/i2c@3180000/sensing_sensors_6";
              };
            };

            camera_module7: module7 {
              status = "okay";
              badge = "sensing_sensors_7";
              position = "7";
              orientation = "1";
              drivernode0 {
                status = "okay";
                pcl_id = "v4l2_sensor";
                devname = "sensing_sensors_7";
                proc-device-tree = "/proc/device-tree/i2c@3180000/sensing_sensors_7";
              };
            };

            camera_module8: module8 {
              status = "okay";
              badge = "sensing_sensors_8";
              position = "8";
              orientation = "1";
              drivernode0 {
                status = "okay";
                pcl_id = "v4l2_sensor";
                devname = "sensing_sensors_8";
                proc-device-tree = "/proc/device-tree/i2c@c250000/sensing_sensors_8";
              };
            };

            camera_module9: module9 {
              status = "okay";
              badge = "sensing_sensors_9";
              position = "9";
              orientation = "1";
              drivernode0 {
                status = "okay";
                pcl_id = "v4l2_sensor";
                devname = "sensing_sensors_9";
                proc-device-tree = "/proc/device-tree/i2c@c250000/sensing_sensors_9";
              };
            };

            camera_module10: module10 {
              status = "okay";
              badge = "sensing_sensors_10";
              position = "10";
              orientation = "1";
              drivernode0 {
                status = "okay";
                pcl_id = "v4l2_sensor";
                devname = "sensing_sensors_10";
                proc-device-tree = "/proc/device-tree/i2c@c250000/sensing_sensors_10";
              };
            };

            camera_module11: module11 {
              status = "okay";
              badge = "sensing_sensors_11";
              position = "11";
              orientation = "1";
              drivernode0 {
                status = "okay";
                pcl_id = "v4l2_sensor";
                devname = "sensing_sensors_11";
                proc-device-tree = "/proc/device-tree/i2c@c250000/sensing_sensors_11";
              };
            };

            camera_module12: module12 {
              status = "okay";
              badge = "sensing_sensors_12";
              position = "12";
              orientation = "1";
              drivernode0 {
                status = "okay";
                pcl_id = "v4l2_sensor";
                devname = "sensing_sensors_12";
                proc-device-tree = "/proc/device-tree/i2c@c250000/sensing_sensors_12";
              };
            };

            camera_module13: module13 {
              status = "okay";
              badge = "sensing_sensors_13";
              position = "13";
              orientation = "1";
              drivernode0 {
                status = "okay";
                pcl_id = "v4l2_sensor";
                devname = "sensing_sensors_13";
                proc-device-tree = "/proc/device-tree/i2c@c250000/sensing_sensors_13";
              };
            };

            camera_module14: module14 {
              status = "okay";
              badge = "sensing_sensors_14";
              position = "14";
              orientation = "1";
              drivernode0 {
                status = "okay";
                pcl_id = "v4l2_sensor";
                devname = "sensing_sensors_14";
                proc-device-tree = "/proc/device-tree/i2c@c250000/sensing_sensors_14";
              };
            };

            camera_module15: module15 {
              status = "okay";
              badge = "sensing_sensors_15";
              position = "15";
              orientation = "1";
              drivernode0 {
                status = "okay";
                pcl_id = "v4l2_sensor";
                devname = "sensing_sensors_15";
                proc-device-tree = "/proc/device-tree/i2c@c250000/sensing_sensors_15";
              };
            };

          }; // end modules
        };
	
};
